VERSION "canboat-NMEA2000-curated"

NS_ :

BS_:

BU_: Vector__XXX
BO_ 2650734848 PGN_130817_furunoSvControl: 24 Vector__XXX
 SG_ Manufacturer_Code : 0|11@1+ (1.0,0) [0|2047] "" Vector__XXX
 SG_ Industry_Code : 13|3@1+ (1.0,0) [0|7] "" Vector__XXX
 SG_ F4 : 16|8@1+ (1.0,0) [0|255] "" Vector__XXX
 SG_ F5 : 24|8@1+ (1.0,0) [0|255] "" Vector__XXX
 SG_ SBAS_mode : 32|8@1+ (1.0,0) [0|255] "" Vector__XXX
 SG_ SBAS_satellite : 40|8@1+ (1.0,0) [0|255] "" Vector__XXX
 SG_ F8 : 48|16@1+ (1.0,0) [0|65535] "" Vector__XXX
 SG_ GPS_disable : 64|32@1+ (1.0,0) [0|4294967295] "" Vector__XXX
 SG_ GLONASS_disable : 96|32@1+ (1.0,0) [0|4294967295] "" Vector__XXX
 SG_ Galileo_disable : 128|40@1+ (1.0,0) [0|1099511627775] "" Vector__XXX
 SG_ QZSS_disable : 168|24@1+ (1.0,0) [0|16777215] "" Vector__XXX

BO_ 2650734848 PGN_130817_lowranceProductInformation: 113 Vector__XXX
 SG_ Manufacturer_Code : 0|11@1+ (1.0,0) [0|2047] "" Vector__XXX
 SG_ Industry_Code : 13|3@1+ (1.0,0) [0|7] "" Vector__XXX
 SG_ Product_Code : 16|16@1+ (1.0,0) [0|65535] "" Vector__XXX
 SG_ Model : 32|256@1+ (1.0,0) [0|115792089237316195423570985008687907853269984665640564039457584007913129639935] "" Vector__XXX
 SG_ A : 288|8@1+ (1.0,0) [0|255] "" Vector__XXX
 SG_ B : 296|8@1+ (1.0,0) [0|255] "" Vector__XXX
 SG_ C : 304|8@1+ (1.0,0) [0|255] "" Vector__XXX
 SG_ Firmware_version : 312|80@1+ (1.0,0) [0|1208925819614629174706175] "" Vector__XXX
 SG_ Firmware_date : 392|256@1+ (1.0,0) [0|115792089237316195423570985008687907853269984665640564039457584007913129639935] "" Vector__XXX
 SG_ Firmware_time : 648|256@1+ (1.0,0) [0|115792089237316195423570985008687907853269984665640564039457584007913129639935] "" Vector__XXX

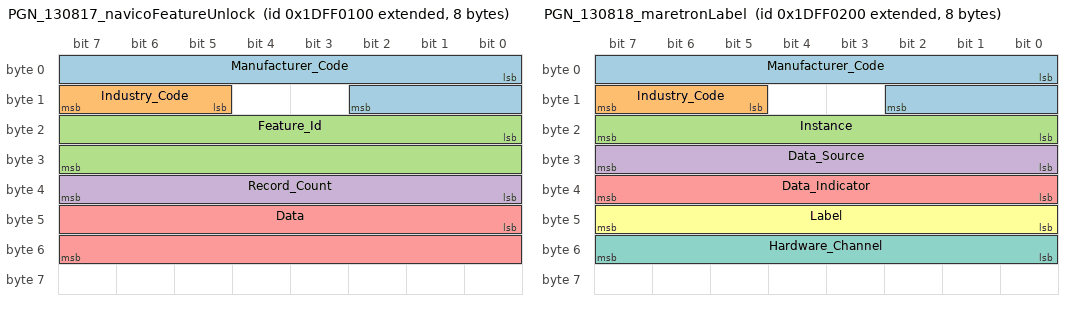
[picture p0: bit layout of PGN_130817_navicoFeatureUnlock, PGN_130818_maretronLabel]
BO_ 2650734848 PGN_130817_navicoFeatureUnlock: 8 Vector__XXX
 SG_ Manufacturer_Code : 0|11@1+ (1.0,0) [0|2047] "" Vector__XXX
 SG_ Industry_Code : 13|3@1+ (1.0,0) [0|7] "" Vector__XXX
 SG_ Feature_Id : 16|16@1+ (1.0,0) [0|65535] "" Vector__XXX
 SG_ Record_Count : 32|8@1+ (1.0,0) [0|255] "" Vector__XXX
 SG_ Data : 40|16@1+ (1.0,0) [0|65535] "" Vector__XXX

BO_ 2583626240 PGN_130818_bepMarineProprietaryPgn130818: 223 Vector__XXX
 SG_ Manufacturer_Code : 0|11@1+ (1.0,0) [0|2047] "" Vector__XXX
 SG_ Industry_Code : 13|3@1+ (1.0,0) [0|7] "" Vector__XXX
 SG_ Data : 16|1768@1+ (1.0,0) [0|16635364987126134419907490844611231857889171561340108669757218330385068731224834608417815051548234195819468783937845710359164977421616154908223175941492902641772198991471137845920843845811776377869137773379678289214194183661112800944378464511794046030758602257005203964634516091405743061582849883160885255175229773660916874237270946647032424101972117051870087763059119895517977437771543686400460392041962138103436564399831189767740372774280024852942859855049773927338342604171805121253257539126169331943684033945189625789470637817855] "" Vector__XXX

BO_ 2650735104 PGN_130818_furunoSensorSetup: 28 Vector__XXX
 SG_ Manufacturer_Code : 0|11@1+ (1.0,0) [0|2047] "" Vector__XXX
 SG_ Industry_Code : 13|3@1+ (1.0,0) [0|7] "" Vector__XXX
 SG_ Rotation_smoothing : 16|16@1+ (0.1,0) [0.0|6553.5] "" Vector__XXX
 SG_ Heading_offset : 32|16@1- (0.1,0) [-3276.8|3276.7000000000003] "deg" Vector__XXX
 SG_ Pitch_offset : 48|16@1- (0.1,0) [-3276.8|3276.7000000000003] "deg" Vector__XXX
 SG_ Roll_offset : 64|16@1- (0.1,0) [-3276.8|3276.7000000000003] "deg" Vector__XXX
 SG_ F8 : 80|8@1+ (1.0,0) [0|255] "" Vector__XXX
 SG_ F9 : 88|8@1+ (1.0,0) [0|255] "" Vector__XXX
 SG_ SOG_and_COG_smoothing : 96|32@1- (0.001,0) [-2147483.648|2147483.647] "" Vector__XXX
 SG_ _3_Axis_speed_smoothing : 128|32@1- (0.001,0) [-2147483.648|2147483.647] "" Vector__XXX
 SG_ FC : 160|16@1+ (1.0,0) [0|65535] "" Vector__XXX
 SG_ _3_axis_offset : 176|16@1- (0.00032,0) [-12.5|12.5] "%" Vector__XXX
 SG_ Air_pressure_offset : 192|16@1- (10.0,0) [-99.9|99.9] "Pa" Vector__XXX
 SG_ Air_temperature_offset : 208|16@1- (0.1,0) [-99.9|99.9] "K" Vector__XXX

BO_ 2650735104 PGN_130818_maretronLabel: 8 Vector__XXX
 SG_ Manufacturer_Code : 0|11@1+ (1.0,0) [0|2047] "" Vector__XXX
 SG_ Industry_Code : 13|3@1+ (1.0,0) [0|7] "" Vector__XXX
 SG_ Instance : 16|8@1+ (1.0,0) [0|255] "" Vector__XXX
 SG_ Data_Source : 24|8@1+ (1.0,0) [0|255] "" Vector__XXX
 SG_ Data_Indicator : 32|8@1+ (1.0,0) [0|255] "" Vector__XXX
 SG_ Label : 40|8@1+ (1.0,0) [0|255] "" Vector__XXX
 SG_ Hardware_Channel : 48|8@1+ (1.0,0) [0|255] "" Vector__XXX

BO_ 2650735104 PGN_130818_simnetReprogramData: 223 Vector__XXX
 SG_ Manufacturer_Code : 0|11@1+ (1.0,0) [0|2047] "" Vector__XXX
 SG_ Industry_Code : 13|3@1+ (1.0,0) [0|7] "" Vector__XXX
 SG_ Version : 16|16@1+ (1.0,0) [0|65535] "" Vector__XXX
 SG_ Sequence : 32|16@1+ (1.0,0) [0|65535] "" Vector__XXX
 SG_ Data : 48|1736@1+ (1.0,0) [0|3873222737369624529943682915673412349514935994832801788523145562593142672261417519398456218547242273534524437025619137650161277833770996636763023198929825481439986962701924575008648411792650906804282631114981670215305449362172000330029629290055959958294081095840130924394940047386508216518640956646037580253377038440880569218953826149700308242340599431626053471830468600503629408257907183468449020768041288969907109718730484547033061453672131722081187147425900662163817930075294599228831366432404455715716824388408480628735] "" Vector__XXX

BO_ 2583626240 PGN_130818_webastoStatus2: 14 Vector__XXX
 SG_ Manufacturer_Code : 0|11@1+ (1.0,0) [0|2047] "" Vector__XXX
 SG_ Industry_Code : 13|3@1+ (1.0,0) [0|7] "" Vector__XXX
 SG_ CAN_Address : 16|8@1+ (1.0,0) [0|255] "" Vector__XXX
 SG_ Device_ID : 24|8@1+ (1.0,0) [0|255] "" Vector__XXX
 SG_ System_Error : 32|32@1+ (1.0,0) [0|4294967295] "" Vector__XXX
 SG_ System_Status : 64|32@1+ (1.0,0) [0|4294967295] "" Vector__XXX
 SG_ Fresh_Air_Blower_Speed : 96|8@1+ (1.0,0) [0|255] "" Vector__XXX
 SG_ V_Series_Output : 104|8@1+ (1.0,0) [0|255] "" Vector__XXX

BO_ 2583626496 PGN_130819_bepMarineCzone130819: 15 Vector__XXX
 SG_ Manufacturer_Code : 0|11@1+ (1.0,0) [0|2047] "" Vector__XXX
 SG_ Industry_Code : 13|3@1+ (1.0,0) [0|7] "" Vector__XXX
 SG_ Field_A : 16|16@1+ (1.0,0) [0|65535] "" Vector__XXX
 SG_ Field_B : 32|8@1+ (1.0,0) [0|255] "" Vector__XXX
 SG_ Field_C : 40|8@1+ (1.0,0) [0|255] "" Vector__XXX
 SG_ Field_D : 48|8@1+ (1.0,0) [0|255] "" Vector__XXX
 SG_ Field_E : 56|16@1+ (1.0,0) [0|65535] "" Vector__XXX
 SG_ Field_F : 72|32@1+ (1.0,0) [0|4294967295] "" Vector__XXX
 SG_ Field_G : 104|8@1+ (1.0,0) [0|255] "" Vector__XXX
 SG_ Flag : 112|8@1+ (1.0,0) [0|255] "" Vector__XXX

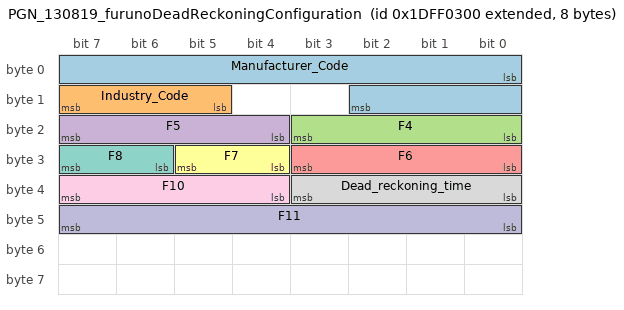
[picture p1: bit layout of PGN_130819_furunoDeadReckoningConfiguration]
BO_ 2650735360 PGN_130819_furunoDeadReckoningConfiguration: 8 Vector__XXX
 SG_ Manufacturer_Code : 0|11@1+ (1.0,0) [0|2047] "" Vector__XXX
 SG_ Industry_Code : 13|3@1+ (1.0,0) [0|7] "" Vector__XXX
 SG_ F4 : 16|4@1+ (1.0,0) [0|15] "" Vector__XXX
 SG_ F5 : 20|4@1+ (1.0,0) [0|15] "" Vector__XXX
 SG_ F6 : 24|4@1+ (1.0,0) [0|15] "" Vector__XXX
 SG_ F7 : 28|2@1+ (1.0,0) [0|3] "" Vector__XXX
 SG_ F8 : 30|2@1+ (1.0,0) [0|3] "" Vector__XXX
 SG_ Dead_reckoning_time : 32|4@1+ (1.0,0) [0|15] "" Vector__XXX
 SG_ F10 : 36|4@1+ (1.0,0) [0|15] "" Vector__XXX
 SG_ F11 : 40|8@1+ (1.0,0) [0|255] "" Vector__XXX

BO_ 2650735360 PGN_130819_maretronAlertTransmission: 34 Vector__XXX
 SG_ Manufacturer_Code : 0|11@1+ (1.0,0) [0|2047] "" Vector__XXX
 SG_ Industry_Code : 13|3@1+ (1.0,0) [0|7] "" Vector__XXX
 SG_ Alert_Type : 16|4@1+ (1.0,0) [0|15] "" Vector__XXX
 SG_ Alert_Category : 20|4@1+ (1.0,0) [0|15] "" Vector__XXX
 SG_ Alert_System : 24|8@1+ (1.0,0) [0|255] "" Vector__XXX
 SG_ Alert_Sub_System : 32|8@1+ (1.0,0) [0|255] "" Vector__XXX
 SG_ Alert_ID : 40|16@1+ (1.0,0) [0|65535] "" Vector__XXX
 SG_ Data_Source_Network_ID_NAME : 56|64@1+ (1.0,0) [0|18446744073709551615] "" Vector__XXX
 SG_ Data_Source_Instance : 120|8@1+ (1.0,0) [0|255] "" Vector__XXX
 SG_ Data_Source_Index_Source : 128|8@1+ (1.0,0) [0|255] "" Vector__XXX
 SG_ Alert_Occurrence_Number : 136|8@1+ (1.0,0) [0|255] "" Vector__XXX
 SG_ Maretron_Extension : 144|128@1+ (1.0,0) [0|340282366920938463463374607431768211455] "" Vector__XXX

BO_ 2650735360 PGN_130819_simnetRequestReprogram: 8 Vector__XXX
 SG_ Manufacturer_Code : 0|11@1+ (1.0,0) [0|2047] "" Vector__XXX
 SG_ Industry_Code : 13|3@1+ (1.0,0) [0|7] "" Vector__XXX

BO_ 2382299904 PGN_130819_webastoHvacCommand: 9 Vector__XXX
 SG_ Manufacturer_Code : 0|11@1+ (1.0,0) [0|2047] "" Vector__XXX
 SG_ Industry_Code : 13|3@1+ (1.0,0) [0|7] "" Vector__XXX
 SG_ CAN_Address : 16|8@1+ (1.0,0) [0|255] "" Vector__XXX
 SG_ Blower_Speed : 24|8@1+ (1.0,0) [0|255] "" Vector__XXX
 SG_ Unit_On_Off : 32|2@1+ (1.0,0) [0|3] "" Vector__XXX
 SG_ Set_Temperature : 40|16@1+ (0.01,0) [0.0|655.35] "" Vector__XXX
 SG_ ECO_Mode : 56|2@1+ (1.0,0) [0|3] "" Vector__XXX
 SG_ Functional_Mode : 58|2@1+ (1.0,0) [0|3] "" Vector__XXX
 SG_ Compressor : 60|2@1+ (1.0,0) [0|3] "" Vector__XXX
 SG_ Mask : 64|8@1+ (1.0,0) [0|255] "" Vector__XXX

BO_ 2583626752 PGN_130820_bepMarineCzoneAlarmStringResponse: 222 Vector__XXX
 SG_ Manufacturer_Code : 0|11@1+ (1.0,0) [0|2047] "" Vector__XXX
 SG_ Industry_Code : 13|3@1+ (1.0,0) [0|7] "" Vector__XXX
 SG_ Device_ID : 16|8@1+ (1.0,0) [0|255] "" Vector__XXX
 SG_ Channel : 24|16@1+ (1.0,0) [0|65535] "" Vector__XXX
 SG_ String : 40|1736@1+ (1.0,0) [0|3873222737369624529943682915673412349514935994832801788523145562593142672261417519398456218547242273534524437025619137650161277833770996636763023198929825481439986962701924575008648411792650906804282631114981670215305449362172000330029629290055959958294081095840130924394940047386508216518640956646037580253377038440880569218953826149700308242340599431626053471830468600503629408257907183468449020768041288969907109718730484547033061453672131722081187147425900662163817930075294599228831366432404455715716824388408480628735] "" Vector__XXX

BO_ 2650735616 PGN_130820_furunoUnknown130820: 8 Vector__XXX

BO_ 2650735616 PGN_130820_fusionAlbumName: 10 Vector__XXX

BO_ 2650735616 PGN_130820_fusionArtistName: 10 Vector__XXX

BO_ 2650735616 PGN_130820_fusionAuxGain: 8 Vector__XXX

BO_ 2650735616 PGN_130820_fusionBalance: 8 Vector__XXX

BO_ 2650735616 PGN_130820_fusionCapabilities: 14 Vector__XXX

BO_ 2650735616 PGN_130820_fusionDeviceName: 8 Vector__XXX

BO_ 2650735616 PGN_130820_fusionEq: 8 Vector__XXX

BO_ 2650735616 PGN_130820_fusionIgnitionSwitchState: 8 Vector__XXX

BO_ 2650735616 PGN_130820_fusionLineLevelControl: 8 Vector__XXX

BO_ 2650735616 PGN_130820_fusionLowPassFilter: 8 Vector__XXX

BO_ 2650735616 PGN_130820_fusionMarineScanMode: 8 Vector__XXX

BO_ 2650735616 PGN_130820_fusionMarineSquelch: 8 Vector__XXX

BO_ 2650735616 PGN_130820_fusionMarineTuner: 8 Vector__XXX

BO_ 2650735616 PGN_130820_fusionMedia: 23 Vector__XXX

BO_ 2650735616 PGN_130820_fusionMenuActionStatus: 11 Vector__XXX

BO_ 2650735616 PGN_130820_fusionMenuCount: 10 Vector__XXX

BO_ 2650735616 PGN_130820_fusionMenuItem: 12 Vector__XXX

BO_ 2650735616 PGN_130820_fusionMenuLockId: 9 Vector__XXX

BO_ 2650735616 PGN_130820_fusionMono: 8 Vector__XXX

BO_ 2650735616 PGN_130820_fusionMultiroom: 9 Vector__XXX

BO_ 2650735616 PGN_130820_fusionMultiroomStatus: 8 Vector__XXX

BO_ 2650735616 PGN_130820_fusionMute: 8 Vector__XXX

BO_ 2650735616 PGN_130820_fusionPowerState: 8 Vector__XXX

BO_ 2650735616 PGN_130820_fusionProcessingBypass: 8 Vector__XXX

BO_ 2650735616 PGN_130820_fusionRdsData: 39 Vector__XXX

BO_ 2650735616 PGN_130820_fusionSetting: 12 Vector__XXX

BO_ 2650735616 PGN_130820_fusionSettings: 9 Vector__XXX

BO_ 2650735616 PGN_130820_fusionSiriusxm: 10 Vector__XXX

BO_ 2650735616 PGN_130820_fusionSiriusxmArtist: 8 Vector__XXX

BO_ 2650735616 PGN_130820_fusionSiriusxmCategory: 8 Vector__XXX

BO_ 2650735616 PGN_130820_fusionSiriusxmChannel: 8 Vector__XXX

BO_ 2650735616 PGN_130820_fusionSiriusxmContentInfo: 8 Vector__XXX

BO_ 2650735616 PGN_130820_fusionSiriusxmPresets: 8 Vector__XXX

BO_ 2650735616 PGN_130820_fusionSiriusxmSignal: 8 Vector__XXX

BO_ 2650735616 PGN_130820_fusionSiriusxmTitle: 8 Vector__XXX

BO_ 2650735616 PGN_130820_fusionSource: 9 Vector__XXX

BO_ 2650735616 PGN_130820_fusionSourceCount: 8 Vector__XXX

BO_ 2650735616 PGN_130820_fusionSpeedVolumeCurrentSpeed: 8 Vector__XXX

BO_ 2650735616 PGN_130820_fusionSublevels: 8 Vector__XXX

BO_ 2650735616 PGN_130820_fusionTrackName: 10 Vector__XXX

BO_ 2650735616 PGN_130820_fusionTrackPosition: 8 Vector__XXX

BO_ 2650735616 PGN_130820_fusionTuner: 12 Vector__XXX

BO_ 2650735616 PGN_130820_fusionUsbRepeatStatus: 12 Vector__XXX

BO_ 2650735616 PGN_130820_fusionVersions: 11 Vector__XXX

BO_ 2650735616 PGN_130820_fusionVolumeLimits: 8 Vector__XXX

BO_ 2650735616 PGN_130820_fusionVolumes: 8 Vector__XXX

BO_ 2650735616 PGN_130820_fusionZoneName: 8 Vector__XXX

BO_ 2650735616 PGN_130820_maretronAlertResponse: 27 Vector__XXX

BO_ 2650735616 PGN_130820_simnetReprogramStatus: 8 Vector__XXX

CM_ BO_ 2650734848 "NMEA2000: PGN 130817 - Furuno: SV control (type: Fast)";
CM_ BO_ 2650734848 "NMEA2000: PGN 130817 - Lowrance: Product Information (type: Fast)";
CM_ BO_ 2650734848 "NMEA2000: PGN 130817 - Navico: Feature Unlock (type: Fast)";
CM_ BO_ 2583626240 "NMEA2000: PGN 130818 - BEP Marine: Proprietary PGN 130818 (type: Fast)";
CM_ BO_ 2650735104 "NMEA2000: PGN 130818 - Furuno: Sensor setup (type: Fast)";
CM_ BO_ 2650735104 "NMEA2000: PGN 130818 - Maretron: Label (type: Fast)";
CM_ BO_ 2650735104 "NMEA2000: PGN 130818 - Simnet: Reprogram Data (type: Fast)";
CM_ BO_ 2583626240 "NMEA2000: PGN 130818 - Webasto: Status 2 (type: Fast)";
CM_ BO_ 2583626496 "NMEA2000: PGN 130819 - BEP Marine: CZone 130819 (type: Fast)";
CM_ BO_ 2650735360 "NMEA2000: PGN 130819 - Furuno: Dead Reckoning Configuration (type: Fast)";
CM_ BO_ 2650735360 "NMEA2000: PGN 130819 - Maretron: Alert Transmission (type: Fast)";
CM_ BO_ 2650735360 "NMEA2000: PGN 130819 - Simnet: Request Reprogram (type: Fast)";
CM_ BO_ 2382299904 "NMEA2000: PGN 130819 - Webasto: HVAC Command (type: Fast)";
CM_ BO_ 2583626752 "NMEA2000: PGN 130820 - BEP Marine: CZone Alarm String Response (type: Fast)";
CM_ BO_ 2650735616 "NMEA2000: PGN 130820 - Furuno: Unknown 130820 (type: Fast)";
CM_ BO_ 2650735616 "NMEA2000: PGN 130820 - Fusion: Album Name (type: Fast)";
CM_ BO_ 2650735616 "NMEA2000: PGN 130820 - Fusion: Artist Name (type: Fast)";
CM_ BO_ 2650735616 "NMEA2000: PGN 130820 - Fusion: Aux Gain (type: Fast)";
CM_ BO_ 2650735616 "NMEA2000: PGN 130820 - Fusion: Balance (type: Fast)";
CM_ BO_ 2650735616 "NMEA2000: PGN 130820 - Fusion: Capabilities (type: Fast)";
CM_ BO_ 2650735616 "NMEA2000: PGN 130820 - Fusion: Device Name (type: Fast)";
CM_ BO_ 2650735616 "NMEA2000: PGN 130820 - Fusion: EQ (type: Fast)";
CM_ BO_ 2650735616 "NMEA2000: PGN 130820 - Fusion: Ignition Switch State (type: Fast)";
CM_ BO_ 2650735616 "NMEA2000: PGN 130820 - Fusion: Line Level Control (type: Fast)";
CM_ BO_ 2650735616 "NMEA2000: PGN 130820 - Fusion: Low Pass Filter (type: Fast)";
CM_ BO_ 2650735616 "NMEA2000: PGN 130820 - Fusion: Marine Scan Mode (type: Fast)";
CM_ BO_ 2650735616 "NMEA2000: PGN 130820 - Fusion: Marine Squelch (type: Fast)";
CM_ BO_ 2650735616 "NMEA2000: PGN 130820 - Fusion: MARINE_TUNER (type: Fast)";
CM_ BO_ 2650735616 "NMEA2000: PGN 130820 - Fusion: Media (type: Fast)";
CM_ BO_ 2650735616 "NMEA2000: PGN 130820 - Fusion: Menu Action Status (type: Fast)";
CM_ BO_ 2650735616 "NMEA2000: PGN 130820 - Fusion: Menu Count (type: Fast)";
CM_ BO_ 2650735616 "NMEA2000: PGN 130820 - Fusion: Menu Item (type: Fast)";
CM_ BO_ 2650735616 "NMEA2000: PGN 130820 - Fusion: Menu Lock Id (type: Fast)";
CM_ BO_ 2650735616 "NMEA2000: PGN 130820 - Fusion: Mono (type: Fast)";
CM_ BO_ 2650735616 "NMEA2000: PGN 130820 - Fusion: Multiroom (type: Fast)";
CM_ BO_ 2650735616 "NMEA2000: PGN 130820 - Fusion: Multiroom Status (type: Fast)";
CM_ BO_ 2650735616 "NMEA2000: PGN 130820 - Fusion: Mute (type: Fast)";
CM_ BO_ 2650735616 "NMEA2000: PGN 130820 - Fusion: Power State (type: Fast)";
CM_ BO_ 2650735616 "NMEA2000: PGN 130820 - Fusion: Processing Bypass (type: Fast)";
CM_ BO_ 2650735616 "NMEA2000: PGN 130820 - Fusion: RDS Data (type: Fast)";
CM_ BO_ 2650735616 "NMEA2000: PGN 130820 - Fusion: Setting (type: Fast)";
CM_ BO_ 2650735616 "NMEA2000: PGN 130820 - Fusion: Settings (type: Fast)";
CM_ BO_ 2650735616 "NMEA2000: PGN 130820 - Fusion: SiriusXM (type: Fast)";
CM_ BO_ 2650735616 "NMEA2000: PGN 130820 - Fusion: SiriusXM Artist (type: Fast)";
CM_ BO_ 2650735616 "NMEA2000: PGN 130820 - Fusion: SiriusXM Category (type: Fast)";
CM_ BO_ 2650735616 "NMEA2000: PGN 130820 - Fusion: SiriusXM Channel (type: Fast)";
CM_ BO_ 2650735616 "NMEA2000: PGN 130820 - Fusion: SiriusXM Content Info (type: Fast)";
CM_ BO_ 2650735616 "NMEA2000: PGN 130820 - Fusion: SiriusXM Presets (type: Fast)";
CM_ BO_ 2650735616 "NMEA2000: PGN 130820 - Fusion: SiriusXM Signal (type: Fast)";
CM_ BO_ 2650735616 "NMEA2000: PGN 130820 - Fusion: SiriusXM Title (type: Fast)";
CM_ BO_ 2650735616 "NMEA2000: PGN 130820 - Fusion: Source (type: Fast)";
CM_ BO_ 2650735616 "NMEA2000: PGN 130820 - Fusion: Source Count (type: Fast)";
CM_ BO_ 2650735616 "NMEA2000: PGN 130820 - Fusion: Speed Volume Current Speed (type: Fast)";
CM_ BO_ 2650735616 "NMEA2000: PGN 130820 - Fusion: Sublevels (type: Fast)";
CM_ BO_ 2650735616 "NMEA2000: PGN 130820 - Fusion: Track Name (type: Fast)";
CM_ BO_ 2650735616 "NMEA2000: PGN 130820 - Fusion: Track Position (type: Fast)";
CM_ BO_ 2650735616 "NMEA2000: PGN 130820 - Fusion: Tuner (type: Fast)";
CM_ BO_ 2650735616 "NMEA2000: PGN 130820 - Fusion: USB Repeat Status (type: Fast)";
CM_ BO_ 2650735616 "NMEA2000: PGN 130820 - Fusion: Versions (type: Fast)";
CM_ BO_ 2650735616 "NMEA2000: PGN 130820 - Fusion: Volume Limits (type: Fast)";
CM_ BO_ 2650735616 "NMEA2000: PGN 130820 - Fusion: Volumes (type: Fast)";
CM_ BO_ 2650735616 "NMEA2000: PGN 130820 - Fusion: Zone Name (type: Fast)";
CM_ BO_ 2650735616 "NMEA2000: PGN 130820 - Maretron: Alert Response (type: Fast)";
CM_ BO_ 2650735616 "NMEA2000: PGN 130820 - Simnet: Reprogram Status (type: Fast)";
CM_ SG_ 2650734848 Manufacturer_Code "Furuno; canboat type: LOOKUP";
CM_ SG_ 2650734848 Industry_Code "Marine Industry; canboat type: LOOKUP";
CM_ SG_ 2650734848 F4 "Unknown; canboat type: BINARY";
CM_ SG_ 2650734848 F5 "Unknown; canboat type: BINARY";
CM_ SG_ 2650734848 SBAS_mode "canboat type: LOOKUP";
CM_ SG_ 2650734848 SBAS_satellite "canboat type: LOOKUP";
CM_ SG_ 2650734848 F8 "Unknown; canboat type: BINARY";
CM_ SG_ 2650734848 GPS_disable "canboat type: BITLOOKUP";
CM_ SG_ 2650734848 GLONASS_disable "canboat type: BITLOOKUP";
CM_ SG_ 2650734848 Galileo_disable "canboat type: BITLOOKUP";
CM_ SG_ 2650734848 QZSS_disable "canboat type: BITLOOKUP";
CM_ SG_ 2650734848 Manufacturer_Code "Lowrance; canboat type: LOOKUP";
CM_ SG_ 2650734848 Industry_Code "Marine Industry; canboat type: LOOKUP";
CM_ SG_ 2650734848 Product_Code "canboat type: UINT16";
CM_ SG_ 2650734848 Model "canboat type: STRING_FIX";
CM_ SG_ 2650734848 A "canboat type: UINT8";
CM_ SG_ 2650734848 B "canboat type: UINT8";
CM_ SG_ 2650734848 C "canboat type: UINT8";
CM_ SG_ 2650734848 Firmware_version "canboat type: STRING_FIX";
CM_ SG_ 2650734848 Firmware_date "canboat type: STRING_FIX";
CM_ SG_ 2650734848 Firmware_time "canboat type: STRING_FIX";
CM_ SG_ 2650734848 Manufacturer_Code "Navico; canboat type: LOOKUP";
CM_ SG_ 2650734848 Industry_Code "Marine Industry; canboat type: LOOKUP";
CM_ SG_ 2650734848 Feature_Id "Feature/object identifier. A 126208 Request for this PGN filters on this value as its field 4 (the requester asks the target to report a specific feature).; canboat type: UINT16";
CM_ SG_ 2650734848 Record_Count "Number of 3-byte records that follow; 0 in every observed broadcast; canboat type: UINT8";
CM_ SG_ 2650734848 Data "Trailing value (observed only with Record Count 0); canboat type: UINT16";
CM_ SG_ 2583626240 Manufacturer_Code "BEP Marine; canboat type: LOOKUP";
CM_ SG_ 2583626240 Industry_Code "Marine Industry; canboat type: LOOKUP";
CM_ SG_ 2583626240 Data "canboat type: BINARY";
CM_ SG_ 2650735104 Manufacturer_Code "Furuno; canboat type: LOOKUP";
CM_ SG_ 2650735104 Industry_Code "Marine Industry; canboat type: LOOKUP";
CM_ SG_ 2650735104 Rotation_smoothing "canboat type: DURATION_UFIX16_DS";
CM_ SG_ 2650735104 Heading_offset "canboat type: ANGLE_FIX16_DDEG";
CM_ SG_ 2650735104 Pitch_offset "canboat type: ANGLE_FIX16_DDEG";
CM_ SG_ 2650735104 Roll_offset "canboat type: ANGLE_FIX16_DDEG";
CM_ SG_ 2650735104 F8 "canboat type: UINT8";
CM_ SG_ 2650735104 F9 "canboat type: UINT8";
CM_ SG_ 2650735104 SOG_and_COG_smoothing "canboat type: DURATION_FIX32_MS";
CM_ SG_ 2650735104 _3_Axis_speed_smoothing "canboat type: DURATION_FIX32_MS";
CM_ SG_ 2650735104 FC "canboat type: UINT16";
CM_ SG_ 2650735104 _3_axis_offset "canboat type: INT16";
CM_ SG_ 2650735104 Air_pressure_offset "canboat type: INT16";
CM_ SG_ 2650735104 Air_temperature_offset "canboat type: FIX16_1";
CM_ SG_ 2650735104 Manufacturer_Code "Maretron; canboat type: LOOKUP";
CM_ SG_ 2650735104 Industry_Code "Marine Industry; canboat type: LOOKUP";
CM_ SG_ 2650735104 Instance "canboat type: UINT8";
CM_ SG_ 2650735104 Data_Source "canboat type: UINT8";
CM_ SG_ 2650735104 Data_Indicator "canboat type: UINT8";
CM_ SG_ 2650735104 Label "canboat type: STRING_LAU";
CM_ SG_ 2650735104 Hardware_Channel "canboat type: UINT8";
CM_ SG_ 2650735104 Manufacturer_Code "Simrad; canboat type: LOOKUP";
CM_ SG_ 2650735104 Industry_Code "Marine Industry; canboat type: LOOKUP";
CM_ SG_ 2650735104 Version "canboat type: UINT16";
CM_ SG_ 2650735104 Sequence "canboat type: UINT16";
CM_ SG_ 2650735104 Data "canboat type: BINARY";
CM_ SG_ 2583626240 Manufacturer_Code "Webasto; canboat type: LOOKUP";
CM_ SG_ 2583626240 Industry_Code "Marine Industry; canboat type: LOOKUP";
CM_ SG_ 2583626240 CAN_Address "canboat type: UINT8";
CM_ SG_ 2583626240 Device_ID "canboat type: UINT8";
CM_ SG_ 2583626240 System_Error "canboat type: UINT32";
CM_ SG_ 2583626240 System_Status "canboat type: UINT32";
CM_ SG_ 2583626240 Fresh_Air_Blower_Speed "canboat type: UINT8";
CM_ SG_ 2583626240 V_Series_Output "canboat type: UINT8";
CM_ SG_ 2583626496 Manufacturer_Code "BEP Marine; canboat type: LOOKUP";
CM_ SG_ 2583626496 Industry_Code "Marine Industry; canboat type: LOOKUP";
CM_ SG_ 2583626496 Field_A "uint16 LE; purpose unverified; canboat type: UINT16";
CM_ SG_ 2583626496 Field_B "Pass-through byte; purpose unverified; canboat type: UINT8";
CM_ SG_ 2583626496 Field_C "Pass-through byte; purpose unverified; canboat type: UINT8";
CM_ SG_ 2583626496 Field_D "Pass-through byte; purpose unverified; canboat type: UINT8";
CM_ SG_ 2583626496 Field_E "uint16 LE; purpose unverified; canboat type: UINT16";
CM_ SG_ 2583626496 Field_F "uint32 LE; top byte always 0 (effectively 24-bit). Purpose unverified.; canboat type: UINT32";
CM_ SG_ 2583626496 Field_G "Pass-through byte; purpose unverified; canboat type: UINT8";
CM_ SG_ 2583626496 Flag "Boolean encoded as 0xFE = false, 0xFF = true; purpose unverified; canboat type: UINT8";
CM_ SG_ 2650735360 Manufacturer_Code "Furuno; canboat type: LOOKUP";
CM_ SG_ 2650735360 Industry_Code "Marine Industry; canboat type: LOOKUP";
CM_ SG_ 2650735360 F4 "canboat type: UNSIGNED_INTEGER";
CM_ SG_ 2650735360 F5 "canboat type: UNSIGNED_INTEGER";
CM_ SG_ 2650735360 F6 "canboat type: UNSIGNED_INTEGER";
CM_ SG_ 2650735360 F7 "canboat type: UNSIGNED_INTEGER";
CM_ SG_ 2650735360 F8 "canboat type: UNSIGNED_INTEGER";
CM_ SG_ 2650735360 Dead_reckoning_time "0=5min, 1=4min, 2=3min, 3=2min, 4=1min (code = 5 - minutes); canboat type: UNSIGNED_INTEGER";
CM_ SG_ 2650735360 F10 "canboat type: UNSIGNED_INTEGER";
CM_ SG_ 2650735360 F11 "canboat type: UINT8";
CM_ SG_ 2650735360 Manufacturer_Code "Maretron; canboat type: LOOKUP";
CM_ SG_ 2650735360 Industry_Code "Marine Industry; canboat type: LOOKUP";
CM_ SG_ 2650735360 Alert_Type "canboat type: LOOKUP";
CM_ SG_ 2650735360 Alert_Category "canboat type: LOOKUP";
CM_ SG_ 2650735360 Alert_System "canboat type: UINT8";
CM_ SG_ 2650735360 Alert_Sub_System "canboat type: UINT8";
CM_ SG_ 2650735360 Alert_ID "canboat type: UINT16";
CM_ SG_ 2650735360 Data_Source_Network_ID_NAME "canboat type: ISO_NAME";
CM_ SG_ 2650735360 Data_Source_Instance "canboat type: UINT8";
CM_ SG_ 2650735360 Data_Source_Index_Source "canboat type: UINT8";
CM_ SG_ 2650735360 Alert_Occurrence_Number "canboat type: UINT8";
CM_ SG_ 2650735360 Maretron_Extension "Maretron-specific payload following the standard Alert identity header.; canboat type: BINARY";
CM_ SG_ 2650735360 Manufacturer_Code "Simrad; canboat type: LOOKUP";
CM_ SG_ 2650735360 Industry_Code "Marine Industry; canboat type: LOOKUP";
CM_ SG_ 2382299904 Manufacturer_Code "Webasto; canboat type: LOOKUP";
CM_ SG_ 2382299904 Industry_Code "Marine Industry; canboat type: LOOKUP";
CM_ SG_ 2382299904 CAN_Address "canboat type: UINT8";
CM_ SG_ 2382299904 Blower_Speed "canboat type: UINT8";
CM_ SG_ 2382299904 Unit_On_Off "canboat type: LOOKUP";
CM_ SG_ 2382299904 Set_Temperature "canboat type: TEMPERATURE";
CM_ SG_ 2382299904 ECO_Mode "canboat type: UNSIGNED_INTEGER";
CM_ SG_ 2382299904 Functional_Mode "canboat type: UNSIGNED_INTEGER";
CM_ SG_ 2382299904 Compressor "canboat type: UNSIGNED_INTEGER";
CM_ SG_ 2382299904 Mask "canboat type: UINT8";
CM_ SG_ 2583626752 Manufacturer_Code "BEP Marine; canboat type: LOOKUP";
CM_ SG_ 2583626752 Industry_Code "Marine Industry; canboat type: LOOKUP";
CM_ SG_ 2583626752 Device_ID "Device / source module id, echoed from the triggering PGN 65299; canboat type: UINT8";
CM_ SG_ 2583626752 Channel "Channel / alarm id, echoed from the triggering PGN 65299; canboat type: UINT16";
CM_ SG_ 2583626752 String "Variable-length NUL-terminated alarm string (up to 217 bytes); ASCII or UTF-8 not yet confirmed; canboat type: BINARY";
VAL_ 2650734848 Manufacturer_Code 69 "ARKS Enterprises" 78 "FW Murphy/Enovation Controls" 80 "Twin Disc" 85 "Kohler Power Systems" 88 "Hemisphere GPS" 135 "Airmar" 137 "Maretron" 140 "Lowrance" 144 "Mercury Marine" 147 "Nautibus Electronic" 148 "Blue Water Data" 154 "Westerbeke" 157 "ISSPRO" 161 "Offshore Systems (UK)" 163 "Evinrude/BRP" 165 "CPAC Systems" 168 "Xantrex Technology" 169 "Marlin Technologies" 172 "Yanmar Marine" 174 "Volvo Penta" 176 "Carling Technologies Inc. (Moritz Aerospace)" 185 "Beede Instruments" 192 "Floscan Instrument" 193 "Nobeltec" 198 "Mystic Valley Communications" 199 "Actia" 201 "Disenos Y Technologia" 211 "Digital Switching Systems" 215 "Xintex/Atena" 224 "EMMI NETWORK" 228 "ZF" 229 "Garmin" 233 "Yacht Monitoring Solutions" 235 "Sailormade Marine Telemetry/Tetra Technology" 243 "Eride" 257 "Honda Motor" 272 "Groco" 273 "Actisense" 274 "Amphenol LTW Technology" 275 "Navico" 283 "Hamilton Jet" 285 "Sea Recovery" 286 "Coelmo SRL Italy" 295 "BEP Marine" 304 "Empir Bus" 305 "NovAtel" 306 "Sleipner Motor" 307 "MBW Technologies" 315 "ICOM" 328 "Qwerty" 329 "Dief" 341 "Boening Automationstechnologie" 345 "Korean Maritime University" 351 "Thrane and Thrane" 355 "Mastervolt" 356 "Fischer Panda Generators" 358 "Victron Energy" 370 "Rolls Royce Marine" 373 "Electronic Design" 374 "Northern Lights" 378 "Glendinning" 381 "B & G" 384 "Rose Point Navigation Systems" 385 "Johnson Outdoors Marine Electronics Inc Geonav" 394 "Capi 2" 396 "Beyond Measure" 400 "Livorsi Marine" 404 "ComNav" 409 "Chetco" 419 "Fusion Electronics" 421 "Standard Horizon" 422 "True Heading" 426 "Egersund Marine Electronics" 427 "em-trak Marine Electronics" 431 "Tohatsu Co, JP" 437 "Digital Yacht" 438 "Comar Systems Limited" 440 "Cummins" 443 "VDO (aka Continental-Corporation)" 451 "Parker Hannifin aka Village Marine Tech" 459 "Alltek Marine Electronics" 460 "SAN GIORGIO S.E.I.N" 466 "Veethree Electronics & Marine" 470 "SI-TEX Marine Electronics" 471 "Sea Cross Marine" 475 "GME aka Standard Communications" 476 "Humminbird Marine Electronics" 478 "Ocean Sat" 481 "Chetco Digital Instruments" 493 "Watcheye" 499 "Lcj Capteurs" 502 "Attwood Marine" 503 "Naviop S.R.L." 504 "Vesper Marine" 510 "Marinesoft" 513 "Simarine" 517 "NoLand Engineering" 518 "Transas USA" 529 "National Instruments Korea" 530 "National Marine Electronics Association" 532 "Onwa Marine" 540 "Webasto" 571 "Marinecraft (South Korea)" 573 "McMurdo Group aka Orolia" 578 "Advansea" 579 "KVH" 580 "San Jose Technology" 583 "Yacht Control" 586 "Suzuki Motor" 591 "US Coast Guard" 595 "Ship Module aka Customware" 600 "Aquatic AV" 605 "Aventics" 606 "Intellian" 612 "SamwonIT" 614 "Arlt Tecnologies" 637 "Bavaria Yachts" 641 "Diverse Yacht Services" 644 "Wema U.S.A dba KUS" 658 "Shenzhen Jiuzhou Himunication" 688 "Rockford" 699 "Harman International" 704 "JL Audio" 708 "Lars Thrane" 715 "Autonnic" 717 "Yacht Devices" 734 "REAP Systems" 735 "AEM Performance Electronics" 739 "LxNav" 741 "Littelfuse, Inc (formerly Carling Technologies)" 743 "DaeMyung" 744 "Woosung" 748 "ISOTTA IFRA srl" 773 "Clarion US" 776 "HMI Systems" 777 "Ocean Signal" 778 "Seakeeper" 781 "Poly Planar" 785 "Fischer Panda DE" 795 "Broyda Industries" 796 "Canadian Automotive" 797 "Tides Marine" 798 "Lumishore" 799 "Still Water Designs and Audio" 802 "BJ Technologies (Beneteau)" 803 "Gill Sensors" 811 "Blue Water Desalination" 815 "FLIR" 824 "Undheim Systems" 826 "Lewmar" 838 "TeamSurv" 844 "Fell Marine" 847 "Oceanvolt" 862 "Prospec" 868 "Data Panel" 890 "L3 Technologies" 894 "Rhodan Marine Systems" 896 "Nexfour Solutions" 905 "ASA Electronics" 909 "Marines Co (South Korea)" 911 "Nautic-on" 917 "Sentinel" 929 "JL Marine Systems" 930 "Ecotronix" 944 "Zontisa Marine" 951 "EXOR International" 962 "Timbolier Industries" 963 "TJC Micro" 968 "Cox Powertrain" 969 "Blue Seas" 981 "Kobelt Manufacturing" 992 "Blue Ocean IOT" 997 "Xenta Systems" 999 "Signal K" 1004 "Ultraflex" 1008 "Lintest SmartBoat" 1011 "Soundmax" 1020 "Team Italia Marine (Onyx Marine Automation s.r.l)" 1021 "Entratech" 1022 "ITC" 1029 "The Marine Guardian" 1047 "Sonic" 1051 "ProNav" 1053 "Vetus Maxwell INC." 1056 "Lithium Pros" 1059 "Boatrax" 1062 "Marol Co ltd" 1065 "CALYPSO Instruments" 1066 "Spot Zero Water" 1069 "Lithionics Battery" 1070 "Quick-teck Electronics" 1075 "Uniden America" 1083 "Nauticoncept" 1084 "Shadow-Caster LED lighting" 1085 "Wet Sounds" 1088 "E-T-A Circuit Breakers" 1092 "Scheiber" 1100 "Smart Yachts International Limited" 1109 "Dockmate" 1114 "Bobs Machine" 1118 "L3Harris ASV" 1119 "Balmar" 1120 "Elettromedia" 1127 "Electromaax" 1140 "Across Oceans Systems" 1145 "Kiwi Yachting" 1150 "BSB Artificial Intelligence" 1151 "Orca Technologies" 1154 "TBS Electronics" 1158 "Technoton Electroics" 1160 "MG Energy Systems" 1169 "Sea Machine Robotics" 1171 "Vista Manufacturing" 1183 "Zipwake" 1186 "Sailmon" 1192 "Airmoniq Pro Kft" 1194 "Sierra Marine" 1200 "Xinuo Information Technology (Xiamen)" 1218 "Septentrio" 1233 "NKE Marine Electronics" 1238 "SuperTrack Aps" 1239 "Honda Electronics" 1245 "Raritan Engineering" 1249 "Integrated Power Solutions AG" 1260 "Interactive Technologies" 1283 "LTG-Tech" 1299 "Energy Solutions (UK)" 1300 "WATT Fuel Cell" 1302 "Pro Mainer" 1305 "Dragonfly Energy" 1306 "Koden Electronics" 1311 "Humphree" 1316 "Hinkley Yachts" 1317 "Global Marine Management GmbH (GMM)" 1320 "Triskel Marine" 1330 "Warwick Control Technologies" 1331 "Dolphin Charger" 1337 "Barnacle Systems" 1348 "Radian IoT" 1353 "Ocean LED Marine" 1359 "BluNav" 1361 "OVA (Nantong Saiyang Electronics Co., Ltd)" 1368 "RAD Propulsion" 1369 "Electric Yacht" 1372 "Elco Motor Yachts" 1384 "Tecnoseal Foundry S.r.l" 1385 "Pro Charging Systems" 1389 "EVEX" 1398 "Gobius Sensor Technology" 1403 "Arco Marine" 1408 "Lenco Marine" 1413 "Naocontrol" 1417 "Revatek" 1438 "Aeolionics" 1439 "PredictWind" 1440 "Egis Mobile Electric" 1445 "Starboard Yacht Group" 1446 "Roswell Marine" 1451 "ePropulsion (Guangdong ePropulsion Technology Ltd.)" 1452 "Micro-Air" 1453 "Vital Battery" 1458 "Ride Controller" 1460 "Tocaro Blue" 1461 "Vanquish Yachts" 1471 "FT Technologies" 1478 "Alps Alpine" 1481 "E-Force Marine" 1482 "CMC Marine" 1483 "Nanjing Sandemarine Information Technology" 1850 "Teleflex Marine (SeaStar Solutions)" 1851 "Raymarine" 1852 "Navionics" 1853 "Japan Radio" 1854 "Northstar Technologies" 1855 "Furuno" 1856 "Trimble" 1857 "Simrad" 1858 "Litton" 1859 "Kvasar" 1860 "MMP" 1861 "Vector Cantech" 1862 "Yamaha Marine" 1863 "Faria Instruments" ;
VAL_ 2650734848 Industry_Code 0 "Global" 1 "Highway" 2 "Agriculture" 3 "Construction" 4 "Marine Industry" 5 "Industrial" ;
VAL_ 2650734848 SBAS_mode 0 "Automatic" 1 "Manual" ;
VAL_ 2650734848 SBAS_satellite 0 "120" 1 "121" 2 "122" 3 "123" 4 "124" 5 "125" 6 "126" 7 "127" 8 "128" 9 "129" 10 "130" 11 "131" 12 "132" 13 "133" 14 "134" 15 "135" 16 "136" 17 "137" 18 "138" ;
VAL_ 2650734848 Manufacturer_Code 69 "ARKS Enterprises" 78 "FW Murphy/Enovation Controls" 80 "Twin Disc" 85 "Kohler Power Systems" 88 "Hemisphere GPS" 135 "Airmar" 137 "Maretron" 140 "Lowrance" 144 "Mercury Marine" 147 "Nautibus Electronic" 148 "Blue Water Data" 154 "Westerbeke" 157 "ISSPRO" 161 "Offshore Systems (UK)" 163 "Evinrude/BRP" 165 "CPAC Systems" 168 "Xantrex Technology" 169 "Marlin Technologies" 172 "Yanmar Marine" 174 "Volvo Penta" 176 "Carling Technologies Inc. (Moritz Aerospace)" 185 "Beede Instruments" 192 "Floscan Instrument" 193 "Nobeltec" 198 "Mystic Valley Communications" 199 "Actia" 201 "Disenos Y Technologia" 211 "Digital Switching Systems" 215 "Xintex/Atena" 224 "EMMI NETWORK" 228 "ZF" 229 "Garmin" 233 "Yacht Monitoring Solutions" 235 "Sailormade Marine Telemetry/Tetra Technology" 243 "Eride" 257 "Honda Motor" 272 "Groco" 273 "Actisense" 274 "Amphenol LTW Technology" 275 "Navico" 283 "Hamilton Jet" 285 "Sea Recovery" 286 "Coelmo SRL Italy" 295 "BEP Marine" 304 "Empir Bus" 305 "NovAtel" 306 "Sleipner Motor" 307 "MBW Technologies" 315 "ICOM" 328 "Qwerty" 329 "Dief" 341 "Boening Automationstechnologie" 345 "Korean Maritime University" 351 "Thrane and Thrane" 355 "Mastervolt" 356 "Fischer Panda Generators" 358 "Victron Energy" 370 "Rolls Royce Marine" 373 "Electronic Design" 374 "Northern Lights" 378 "Glendinning" 381 "B & G" 384 "Rose Point Navigation Systems" 385 "Johnson Outdoors Marine Electronics Inc Geonav" 394 "Capi 2" 396 "Beyond Measure" 400 "Livorsi Marine" 404 "ComNav" 409 "Chetco" 419 "Fusion Electronics" 421 "Standard Horizon" 422 "True Heading" 426 "Egersund Marine Electronics" 427 "em-trak Marine Electronics" 431 "Tohatsu Co, JP" 437 "Digital Yacht" 438 "Comar Systems Limited" 440 "Cummins" 443 "VDO (aka Continental-Corporation)" 451 "Parker Hannifin aka Village Marine Tech" 459 "Alltek Marine Electronics" 460 "SAN GIORGIO S.E.I.N" 466 "Veethree Electronics & Marine" 470 "SI-TEX Marine Electronics" 471 "Sea Cross Marine" 475 "GME aka Standard Communications" 476 "Humminbird Marine Electronics" 478 "Ocean Sat" 481 "Chetco Digital Instruments" 493 "Watcheye" 499 "Lcj Capteurs" 502 "Attwood Marine" 503 "Naviop S.R.L." 504 "Vesper Marine" 510 "Marinesoft" 513 "Simarine" 517 "NoLand Engineering" 518 "Transas USA" 529 "National Instruments Korea" 530 "National Marine Electronics Association" 532 "Onwa Marine" 540 "Webasto" 571 "Marinecraft (South Korea)" 573 "McMurdo Group aka Orolia" 578 "Advansea" 579 "KVH" 580 "San Jose Technology" 583 "Yacht Control" 586 "Suzuki Motor" 591 "US Coast Guard" 595 "Ship Module aka Customware" 600 "Aquatic AV" 605 "Aventics" 606 "Intellian" 612 "SamwonIT" 614 "Arlt Tecnologies" 637 "Bavaria Yachts" 641 "Diverse Yacht Services" 644 "Wema U.S.A dba KUS" 658 "Shenzhen Jiuzhou Himunication" 688 "Rockford" 699 "Harman International" 704 "JL Audio" 708 "Lars Thrane" 715 "Autonnic" 717 "Yacht Devices" 734 "REAP Systems" 735 "AEM Performance Electronics" 739 "LxNav" 741 "Littelfuse, Inc (formerly Carling Technologies)" 743 "DaeMyung" 744 "Woosung" 748 "ISOTTA IFRA srl" 773 "Clarion US" 776 "HMI Systems" 777 "Ocean Signal" 778 "Seakeeper" 781 "Poly Planar" 785 "Fischer Panda DE" 795 "Broyda Industries" 796 "Canadian Automotive" 797 "Tides Marine" 798 "Lumishore" 799 "Still Water Designs and Audio" 802 "BJ Technologies (Beneteau)" 803 "Gill Sensors" 811 "Blue Water Desalination" 815 "FLIR" 824 "Undheim Systems" 826 "Lewmar" 838 "TeamSurv" 844 "Fell Marine" 847 "Oceanvolt" 862 "Prospec" 868 "Data Panel" 890 "L3 Technologies" 894 "Rhodan Marine Systems" 896 "Nexfour Solutions" 905 "ASA Electronics" 909 "Marines Co (South Korea)" 911 "Nautic-on" 917 "Sentinel" 929 "JL Marine Systems" 930 "Ecotronix" 944 "Zontisa Marine" 951 "EXOR International" 962 "Timbolier Industries" 963 "TJC Micro" 968 "Cox Powertrain" 969 "Blue Seas" 981 "Kobelt Manufacturing" 992 "Blue Ocean IOT" 997 "Xenta Systems" 999 "Signal K" 1004 "Ultraflex" 1008 "Lintest SmartBoat" 1011 "Soundmax" 1020 "Team Italia Marine (Onyx Marine Automation s.r.l)" 1021 "Entratech" 1022 "ITC" 1029 "The Marine Guardian" 1047 "Sonic" 1051 "ProNav" 1053 "Vetus Maxwell INC." 1056 "Lithium Pros" 1059 "Boatrax" 1062 "Marol Co ltd" 1065 "CALYPSO Instruments" 1066 "Spot Zero Water" 1069 "Lithionics Battery" 1070 "Quick-teck Electronics" 1075 "Uniden America" 1083 "Nauticoncept" 1084 "Shadow-Caster LED lighting" 1085 "Wet Sounds" 1088 "E-T-A Circuit Breakers" 1092 "Scheiber" 1100 "Smart Yachts International Limited" 1109 "Dockmate" 1114 "Bobs Machine" 1118 "L3Harris ASV" 1119 "Balmar" 1120 "Elettromedia" 1127 "Electromaax" 1140 "Across Oceans Systems" 1145 "Kiwi Yachting" 1150 "BSB Artificial Intelligence" 1151 "Orca Technologies" 1154 "TBS Electronics" 1158 "Technoton Electroics" 1160 "MG Energy Systems" 1169 "Sea Machine Robotics" 1171 "Vista Manufacturing" 1183 "Zipwake" 1186 "Sailmon" 1192 "Airmoniq Pro Kft" 1194 "Sierra Marine" 1200 "Xinuo Information Technology (Xiamen)" 1218 "Septentrio" 1233 "NKE Marine Electronics" 1238 "SuperTrack Aps" 1239 "Honda Electronics" 1245 "Raritan Engineering" 1249 "Integrated Power Solutions AG" 1260 "Interactive Technologies" 1283 "LTG-Tech" 1299 "Energy Solutions (UK)" 1300 "WATT Fuel Cell" 1302 "Pro Mainer" 1305 "Dragonfly Energy" 1306 "Koden Electronics" 1311 "Humphree" 1316 "Hinkley Yachts" 1317 "Global Marine Management GmbH (GMM)" 1320 "Triskel Marine" 1330 "Warwick Control Technologies" 1331 "Dolphin Charger" 1337 "Barnacle Systems" 1348 "Radian IoT" 1353 "Ocean LED Marine" 1359 "BluNav" 1361 "OVA (Nantong Saiyang Electronics Co., Ltd)" 1368 "RAD Propulsion" 1369 "Electric Yacht" 1372 "Elco Motor Yachts" 1384 "Tecnoseal Foundry S.r.l" 1385 "Pro Charging Systems" 1389 "EVEX" 1398 "Gobius Sensor Technology" 1403 "Arco Marine" 1408 "Lenco Marine" 1413 "Naocontrol" 1417 "Revatek" 1438 "Aeolionics" 1439 "PredictWind" 1440 "Egis Mobile Electric" 1445 "Starboard Yacht Group" 1446 "Roswell Marine" 1451 "ePropulsion (Guangdong ePropulsion Technology Ltd.)" 1452 "Micro-Air" 1453 "Vital Battery" 1458 "Ride Controller" 1460 "Tocaro Blue" 1461 "Vanquish Yachts" 1471 "FT Technologies" 1478 "Alps Alpine" 1481 "E-Force Marine" 1482 "CMC Marine" 1483 "Nanjing Sandemarine Information Technology" 1850 "Teleflex Marine (SeaStar Solutions)" 1851 "Raymarine" 1852 "Navionics" 1853 "Japan Radio" 1854 "Northstar Technologies" 1855 "Furuno" 1856 "Trimble" 1857 "Simrad" 1858 "Litton" 1859 "Kvasar" 1860 "MMP" 1861 "Vector Cantech" 1862 "Yamaha Marine" 1863 "Faria Instruments" ;
VAL_ 2650734848 Industry_Code 0 "Global" 1 "Highway" 2 "Agriculture" 3 "Construction" 4 "Marine Industry" 5 "Industrial" ;
VAL_ 2650734848 Manufacturer_Code 69 "ARKS Enterprises" 78 "FW Murphy/Enovation Controls" 80 "Twin Disc" 85 "Kohler Power Systems" 88 "Hemisphere GPS" 135 "Airmar" 137 "Maretron" 140 "Lowrance" 144 "Mercury Marine" 147 "Nautibus Electronic" 148 "Blue Water Data" 154 "Westerbeke" 157 "ISSPRO" 161 "Offshore Systems (UK)" 163 "Evinrude/BRP" 165 "CPAC Systems" 168 "Xantrex Technology" 169 "Marlin Technologies" 172 "Yanmar Marine" 174 "Volvo Penta" 176 "Carling Technologies Inc. (Moritz Aerospace)" 185 "Beede Instruments" 192 "Floscan Instrument" 193 "Nobeltec" 198 "Mystic Valley Communications" 199 "Actia" 201 "Disenos Y Technologia" 211 "Digital Switching Systems" 215 "Xintex/Atena" 224 "EMMI NETWORK" 228 "ZF" 229 "Garmin" 233 "Yacht Monitoring Solutions" 235 "Sailormade Marine Telemetry/Tetra Technology" 243 "Eride" 257 "Honda Motor" 272 "Groco" 273 "Actisense" 274 "Amphenol LTW Technology" 275 "Navico" 283 "Hamilton Jet" 285 "Sea Recovery" 286 "Coelmo SRL Italy" 295 "BEP Marine" 304 "Empir Bus" 305 "NovAtel" 306 "Sleipner Motor" 307 "MBW Technologies" 315 "ICOM" 328 "Qwerty" 329 "Dief" 341 "Boening Automationstechnologie" 345 "Korean Maritime University" 351 "Thrane and Thrane" 355 "Mastervolt" 356 "Fischer Panda Generators" 358 "Victron Energy" 370 "Rolls Royce Marine" 373 "Electronic Design" 374 "Northern Lights" 378 "Glendinning" 381 "B & G" 384 "Rose Point Navigation Systems" 385 "Johnson Outdoors Marine Electronics Inc Geonav" 394 "Capi 2" 396 "Beyond Measure" 400 "Livorsi Marine" 404 "ComNav" 409 "Chetco" 419 "Fusion Electronics" 421 "Standard Horizon" 422 "True Heading" 426 "Egersund Marine Electronics" 427 "em-trak Marine Electronics" 431 "Tohatsu Co, JP" 437 "Digital Yacht" 438 "Comar Systems Limited" 440 "Cummins" 443 "VDO (aka Continental-Corporation)" 451 "Parker Hannifin aka Village Marine Tech" 459 "Alltek Marine Electronics" 460 "SAN GIORGIO S.E.I.N" 466 "Veethree Electronics & Marine" 470 "SI-TEX Marine Electronics" 471 "Sea Cross Marine" 475 "GME aka Standard Communications" 476 "Humminbird Marine Electronics" 478 "Ocean Sat" 481 "Chetco Digital Instruments" 493 "Watcheye" 499 "Lcj Capteurs" 502 "Attwood Marine" 503 "Naviop S.R.L." 504 "Vesper Marine" 510 "Marinesoft" 513 "Simarine" 517 "NoLand Engineering" 518 "Transas USA" 529 "National Instruments Korea" 530 "National Marine Electronics Association" 532 "Onwa Marine" 540 "Webasto" 571 "Marinecraft (South Korea)" 573 "McMurdo Group aka Orolia" 578 "Advansea" 579 "KVH" 580 "San Jose Technology" 583 "Yacht Control" 586 "Suzuki Motor" 591 "US Coast Guard" 595 "Ship Module aka Customware" 600 "Aquatic AV" 605 "Aventics" 606 "Intellian" 612 "SamwonIT" 614 "Arlt Tecnologies" 637 "Bavaria Yachts" 641 "Diverse Yacht Services" 644 "Wema U.S.A dba KUS" 658 "Shenzhen Jiuzhou Himunication" 688 "Rockford" 699 "Harman International" 704 "JL Audio" 708 "Lars Thrane" 715 "Autonnic" 717 "Yacht Devices" 734 "REAP Systems" 735 "AEM Performance Electronics" 739 "LxNav" 741 "Littelfuse, Inc (formerly Carling Technologies)" 743 "DaeMyung" 744 "Woosung" 748 "ISOTTA IFRA srl" 773 "Clarion US" 776 "HMI Systems" 777 "Ocean Signal" 778 "Seakeeper" 781 "Poly Planar" 785 "Fischer Panda DE" 795 "Broyda Industries" 796 "Canadian Automotive" 797 "Tides Marine" 798 "Lumishore" 799 "Still Water Designs and Audio" 802 "BJ Technologies (Beneteau)" 803 "Gill Sensors" 811 "Blue Water Desalination" 815 "FLIR" 824 "Undheim Systems" 826 "Lewmar" 838 "TeamSurv" 844 "Fell Marine" 847 "Oceanvolt" 862 "Prospec" 868 "Data Panel" 890 "L3 Technologies" 894 "Rhodan Marine Systems" 896 "Nexfour Solutions" 905 "ASA Electronics" 909 "Marines Co (South Korea)" 911 "Nautic-on" 917 "Sentinel" 929 "JL Marine Systems" 930 "Ecotronix" 944 "Zontisa Marine" 951 "EXOR International" 962 "Timbolier Industries" 963 "TJC Micro" 968 "Cox Powertrain" 969 "Blue Seas" 981 "Kobelt Manufacturing" 992 "Blue Ocean IOT" 997 "Xenta Systems" 999 "Signal K" 1004 "Ultraflex" 1008 "Lintest SmartBoat" 1011 "Soundmax" 1020 "Team Italia Marine (Onyx Marine Automation s.r.l)" 1021 "Entratech" 1022 "ITC" 1029 "The Marine Guardian" 1047 "Sonic" 1051 "ProNav" 1053 "Vetus Maxwell INC." 1056 "Lithium Pros" 1059 "Boatrax" 1062 "Marol Co ltd" 1065 "CALYPSO Instruments" 1066 "Spot Zero Water" 1069 "Lithionics Battery" 1070 "Quick-teck Electronics" 1075 "Uniden America" 1083 "Nauticoncept" 1084 "Shadow-Caster LED lighting" 1085 "Wet Sounds" 1088 "E-T-A Circuit Breakers" 1092 "Scheiber" 1100 "Smart Yachts International Limited" 1109 "Dockmate" 1114 "Bobs Machine" 1118 "L3Harris ASV" 1119 "Balmar" 1120 "Elettromedia" 1127 "Electromaax" 1140 "Across Oceans Systems" 1145 "Kiwi Yachting" 1150 "BSB Artificial Intelligence" 1151 "Orca Technologies" 1154 "TBS Electronics" 1158 "Technoton Electroics" 1160 "MG Energy Systems" 1169 "Sea Machine Robotics" 1171 "Vista Manufacturing" 1183 "Zipwake" 1186 "Sailmon" 1192 "Airmoniq Pro Kft" 1194 "Sierra Marine" 1200 "Xinuo Information Technology (Xiamen)" 1218 "Septentrio" 1233 "NKE Marine Electronics" 1238 "SuperTrack Aps" 1239 "Honda Electronics" 1245 "Raritan Engineering" 1249 "Integrated Power Solutions AG" 1260 "Interactive Technologies" 1283 "LTG-Tech" 1299 "Energy Solutions (UK)" 1300 "WATT Fuel Cell" 1302 "Pro Mainer" 1305 "Dragonfly Energy" 1306 "Koden Electronics" 1311 "Humphree" 1316 "Hinkley Yachts" 1317 "Global Marine Management GmbH (GMM)" 1320 "Triskel Marine" 1330 "Warwick Control Technologies" 1331 "Dolphin Charger" 1337 "Barnacle Systems" 1348 "Radian IoT" 1353 "Ocean LED Marine" 1359 "BluNav" 1361 "OVA (Nantong Saiyang Electronics Co., Ltd)" 1368 "RAD Propulsion" 1369 "Electric Yacht" 1372 "Elco Motor Yachts" 1384 "Tecnoseal Foundry S.r.l" 1385 "Pro Charging Systems" 1389 "EVEX" 1398 "Gobius Sensor Technology" 1403 "Arco Marine" 1408 "Lenco Marine" 1413 "Naocontrol" 1417 "Revatek" 1438 "Aeolionics" 1439 "PredictWind" 1440 "Egis Mobile Electric" 1445 "Starboard Yacht Group" 1446 "Roswell Marine" 1451 "ePropulsion (Guangdong ePropulsion Technology Ltd.)" 1452 "Micro-Air" 1453 "Vital Battery" 1458 "Ride Controller" 1460 "Tocaro Blue" 1461 "Vanquish Yachts" 1471 "FT Technologies" 1478 "Alps Alpine" 1481 "E-Force Marine" 1482 "CMC Marine" 1483 "Nanjing Sandemarine Information Technology" 1850 "Teleflex Marine (SeaStar Solutions)" 1851 "Raymarine" 1852 "Navionics" 1853 "Japan Radio" 1854 "Northstar Technologies" 1855 "Furuno" 1856 "Trimble" 1857 "Simrad" 1858 "Litton" 1859 "Kvasar" 1860 "MMP" 1861 "Vector Cantech" 1862 "Yamaha Marine" 1863 "Faria Instruments" ;
VAL_ 2650734848 Industry_Code 0 "Global" 1 "Highway" 2 "Agriculture" 3 "Construction" 4 "Marine Industry" 5 "Industrial" ;
VAL_ 2583626240 Manufacturer_Code 69 "ARKS Enterprises" 78 "FW Murphy/Enovation Controls" 80 "Twin Disc" 85 "Kohler Power Systems" 88 "Hemisphere GPS" 135 "Airmar" 137 "Maretron" 140 "Lowrance" 144 "Mercury Marine" 147 "Nautibus Electronic" 148 "Blue Water Data" 154 "Westerbeke" 157 "ISSPRO" 161 "Offshore Systems (UK)" 163 "Evinrude/BRP" 165 "CPAC Systems" 168 "Xantrex Technology" 169 "Marlin Technologies" 172 "Yanmar Marine" 174 "Volvo Penta" 176 "Carling Technologies Inc. (Moritz Aerospace)" 185 "Beede Instruments" 192 "Floscan Instrument" 193 "Nobeltec" 198 "Mystic Valley Communications" 199 "Actia" 201 "Disenos Y Technologia" 211 "Digital Switching Systems" 215 "Xintex/Atena" 224 "EMMI NETWORK" 228 "ZF" 229 "Garmin" 233 "Yacht Monitoring Solutions" 235 "Sailormade Marine Telemetry/Tetra Technology" 243 "Eride" 257 "Honda Motor" 272 "Groco" 273 "Actisense" 274 "Amphenol LTW Technology" 275 "Navico" 283 "Hamilton Jet" 285 "Sea Recovery" 286 "Coelmo SRL Italy" 295 "BEP Marine" 304 "Empir Bus" 305 "NovAtel" 306 "Sleipner Motor" 307 "MBW Technologies" 315 "ICOM" 328 "Qwerty" 329 "Dief" 341 "Boening Automationstechnologie" 345 "Korean Maritime University" 351 "Thrane and Thrane" 355 "Mastervolt" 356 "Fischer Panda Generators" 358 "Victron Energy" 370 "Rolls Royce Marine" 373 "Electronic Design" 374 "Northern Lights" 378 "Glendinning" 381 "B & G" 384 "Rose Point Navigation Systems" 385 "Johnson Outdoors Marine Electronics Inc Geonav" 394 "Capi 2" 396 "Beyond Measure" 400 "Livorsi Marine" 404 "ComNav" 409 "Chetco" 419 "Fusion Electronics" 421 "Standard Horizon" 422 "True Heading" 426 "Egersund Marine Electronics" 427 "em-trak Marine Electronics" 431 "Tohatsu Co, JP" 437 "Digital Yacht" 438 "Comar Systems Limited" 440 "Cummins" 443 "VDO (aka Continental-Corporation)" 451 "Parker Hannifin aka Village Marine Tech" 459 "Alltek Marine Electronics" 460 "SAN GIORGIO S.E.I.N" 466 "Veethree Electronics & Marine" 470 "SI-TEX Marine Electronics" 471 "Sea Cross Marine" 475 "GME aka Standard Communications" 476 "Humminbird Marine Electronics" 478 "Ocean Sat" 481 "Chetco Digital Instruments" 493 "Watcheye" 499 "Lcj Capteurs" 502 "Attwood Marine" 503 "Naviop S.R.L." 504 "Vesper Marine" 510 "Marinesoft" 513 "Simarine" 517 "NoLand Engineering" 518 "Transas USA" 529 "National Instruments Korea" 530 "National Marine Electronics Association" 532 "Onwa Marine" 540 "Webasto" 571 "Marinecraft (South Korea)" 573 "McMurdo Group aka Orolia" 578 "Advansea" 579 "KVH" 580 "San Jose Technology" 583 "Yacht Control" 586 "Suzuki Motor" 591 "US Coast Guard" 595 "Ship Module aka Customware" 600 "Aquatic AV" 605 "Aventics" 606 "Intellian" 612 "SamwonIT" 614 "Arlt Tecnologies" 637 "Bavaria Yachts" 641 "Diverse Yacht Services" 644 "Wema U.S.A dba KUS" 658 "Shenzhen Jiuzhou Himunication" 688 "Rockford" 699 "Harman International" 704 "JL Audio" 708 "Lars Thrane" 715 "Autonnic" 717 "Yacht Devices" 734 "REAP Systems" 735 "AEM Performance Electronics" 739 "LxNav" 741 "Littelfuse, Inc (formerly Carling Technologies)" 743 "DaeMyung" 744 "Woosung" 748 "ISOTTA IFRA srl" 773 "Clarion US" 776 "HMI Systems" 777 "Ocean Signal" 778 "Seakeeper" 781 "Poly Planar" 785 "Fischer Panda DE" 795 "Broyda Industries" 796 "Canadian Automotive" 797 "Tides Marine" 798 "Lumishore" 799 "Still Water Designs and Audio" 802 "BJ Technologies (Beneteau)" 803 "Gill Sensors" 811 "Blue Water Desalination" 815 "FLIR" 824 "Undheim Systems" 826 "Lewmar" 838 "TeamSurv" 844 "Fell Marine" 847 "Oceanvolt" 862 "Prospec" 868 "Data Panel" 890 "L3 Technologies" 894 "Rhodan Marine Systems" 896 "Nexfour Solutions" 905 "ASA Electronics" 909 "Marines Co (South Korea)" 911 "Nautic-on" 917 "Sentinel" 929 "JL Marine Systems" 930 "Ecotronix" 944 "Zontisa Marine" 951 "EXOR International" 962 "Timbolier Industries" 963 "TJC Micro" 968 "Cox Powertrain" 969 "Blue Seas" 981 "Kobelt Manufacturing" 992 "Blue Ocean IOT" 997 "Xenta Systems" 999 "Signal K" 1004 "Ultraflex" 1008 "Lintest SmartBoat" 1011 "Soundmax" 1020 "Team Italia Marine (Onyx Marine Automation s.r.l)" 1021 "Entratech" 1022 "ITC" 1029 "The Marine Guardian" 1047 "Sonic" 1051 "ProNav" 1053 "Vetus Maxwell INC." 1056 "Lithium Pros" 1059 "Boatrax" 1062 "Marol Co ltd" 1065 "CALYPSO Instruments" 1066 "Spot Zero Water" 1069 "Lithionics Battery" 1070 "Quick-teck Electronics" 1075 "Uniden America" 1083 "Nauticoncept" 1084 "Shadow-Caster LED lighting" 1085 "Wet Sounds" 1088 "E-T-A Circuit Breakers" 1092 "Scheiber" 1100 "Smart Yachts International Limited" 1109 "Dockmate" 1114 "Bobs Machine" 1118 "L3Harris ASV" 1119 "Balmar" 1120 "Elettromedia" 1127 "Electromaax" 1140 "Across Oceans Systems" 1145 "Kiwi Yachting" 1150 "BSB Artificial Intelligence" 1151 "Orca Technologies" 1154 "TBS Electronics" 1158 "Technoton Electroics" 1160 "MG Energy Systems" 1169 "Sea Machine Robotics" 1171 "Vista Manufacturing" 1183 "Zipwake" 1186 "Sailmon" 1192 "Airmoniq Pro Kft" 1194 "Sierra Marine" 1200 "Xinuo Information Technology (Xiamen)" 1218 "Septentrio" 1233 "NKE Marine Electronics" 1238 "SuperTrack Aps" 1239 "Honda Electronics" 1245 "Raritan Engineering" 1249 "Integrated Power Solutions AG" 1260 "Interactive Technologies" 1283 "LTG-Tech" 1299 "Energy Solutions (UK)" 1300 "WATT Fuel Cell" 1302 "Pro Mainer" 1305 "Dragonfly Energy" 1306 "Koden Electronics" 1311 "Humphree" 1316 "Hinkley Yachts" 1317 "Global Marine Management GmbH (GMM)" 1320 "Triskel Marine" 1330 "Warwick Control Technologies" 1331 "Dolphin Charger" 1337 "Barnacle Systems" 1348 "Radian IoT" 1353 "Ocean LED Marine" 1359 "BluNav" 1361 "OVA (Nantong Saiyang Electronics Co., Ltd)" 1368 "RAD Propulsion" 1369 "Electric Yacht" 1372 "Elco Motor Yachts" 1384 "Tecnoseal Foundry S.r.l" 1385 "Pro Charging Systems" 1389 "EVEX" 1398 "Gobius Sensor Technology" 1403 "Arco Marine" 1408 "Lenco Marine" 1413 "Naocontrol" 1417 "Revatek" 1438 "Aeolionics" 1439 "PredictWind" 1440 "Egis Mobile Electric" 1445 "Starboard Yacht Group" 1446 "Roswell Marine" 1451 "ePropulsion (Guangdong ePropulsion Technology Ltd.)" 1452 "Micro-Air" 1453 "Vital Battery" 1458 "Ride Controller" 1460 "Tocaro Blue" 1461 "Vanquish Yachts" 1471 "FT Technologies" 1478 "Alps Alpine" 1481 "E-Force Marine" 1482 "CMC Marine" 1483 "Nanjing Sandemarine Information Technology" 1850 "Teleflex Marine (SeaStar Solutions)" 1851 "Raymarine" 1852 "Navionics" 1853 "Japan Radio" 1854 "Northstar Technologies" 1855 "Furuno" 1856 "Trimble" 1857 "Simrad" 1858 "Litton" 1859 "Kvasar" 1860 "MMP" 1861 "Vector Cantech" 1862 "Yamaha Marine" 1863 "Faria Instruments" ;
VAL_ 2583626240 Industry_Code 0 "Global" 1 "Highway" 2 "Agriculture" 3 "Construction" 4 "Marine Industry" 5 "Industrial" ;
VAL_ 2650735104 Manufacturer_Code 69 "ARKS Enterprises" 78 "FW Murphy/Enovation Controls" 80 "Twin Disc" 85 "Kohler Power Systems" 88 "Hemisphere GPS" 135 "Airmar" 137 "Maretron" 140 "Lowrance" 144 "Mercury Marine" 147 "Nautibus Electronic" 148 "Blue Water Data" 154 "Westerbeke" 157 "ISSPRO" 161 "Offshore Systems (UK)" 163 "Evinrude/BRP" 165 "CPAC Systems" 168 "Xantrex Technology" 169 "Marlin Technologies" 172 "Yanmar Marine" 174 "Volvo Penta" 176 "Carling Technologies Inc. (Moritz Aerospace)" 185 "Beede Instruments" 192 "Floscan Instrument" 193 "Nobeltec" 198 "Mystic Valley Communications" 199 "Actia" 201 "Disenos Y Technologia" 211 "Digital Switching Systems" 215 "Xintex/Atena" 224 "EMMI NETWORK" 228 "ZF" 229 "Garmin" 233 "Yacht Monitoring Solutions" 235 "Sailormade Marine Telemetry/Tetra Technology" 243 "Eride" 257 "Honda Motor" 272 "Groco" 273 "Actisense" 274 "Amphenol LTW Technology" 275 "Navico" 283 "Hamilton Jet" 285 "Sea Recovery" 286 "Coelmo SRL Italy" 295 "BEP Marine" 304 "Empir Bus" 305 "NovAtel" 306 "Sleipner Motor" 307 "MBW Technologies" 315 "ICOM" 328 "Qwerty" 329 "Dief" 341 "Boening Automationstechnologie" 345 "Korean Maritime University" 351 "Thrane and Thrane" 355 "Mastervolt" 356 "Fischer Panda Generators" 358 "Victron Energy" 370 "Rolls Royce Marine" 373 "Electronic Design" 374 "Northern Lights" 378 "Glendinning" 381 "B & G" 384 "Rose Point Navigation Systems" 385 "Johnson Outdoors Marine Electronics Inc Geonav" 394 "Capi 2" 396 "Beyond Measure" 400 "Livorsi Marine" 404 "ComNav" 409 "Chetco" 419 "Fusion Electronics" 421 "Standard Horizon" 422 "True Heading" 426 "Egersund Marine Electronics" 427 "em-trak Marine Electronics" 431 "Tohatsu Co, JP" 437 "Digital Yacht" 438 "Comar Systems Limited" 440 "Cummins" 443 "VDO (aka Continental-Corporation)" 451 "Parker Hannifin aka Village Marine Tech" 459 "Alltek Marine Electronics" 460 "SAN GIORGIO S.E.I.N" 466 "Veethree Electronics & Marine" 470 "SI-TEX Marine Electronics" 471 "Sea Cross Marine" 475 "GME aka Standard Communications" 476 "Humminbird Marine Electronics" 478 "Ocean Sat" 481 "Chetco Digital Instruments" 493 "Watcheye" 499 "Lcj Capteurs" 502 "Attwood Marine" 503 "Naviop S.R.L." 504 "Vesper Marine" 510 "Marinesoft" 513 "Simarine" 517 "NoLand Engineering" 518 "Transas USA" 529 "National Instruments Korea" 530 "National Marine Electronics Association" 532 "Onwa Marine" 540 "Webasto" 571 "Marinecraft (South Korea)" 573 "McMurdo Group aka Orolia" 578 "Advansea" 579 "KVH" 580 "San Jose Technology" 583 "Yacht Control" 586 "Suzuki Motor" 591 "US Coast Guard" 595 "Ship Module aka Customware" 600 "Aquatic AV" 605 "Aventics" 606 "Intellian" 612 "SamwonIT" 614 "Arlt Tecnologies" 637 "Bavaria Yachts" 641 "Diverse Yacht Services" 644 "Wema U.S.A dba KUS" 658 "Shenzhen Jiuzhou Himunication" 688 "Rockford" 699 "Harman International" 704 "JL Audio" 708 "Lars Thrane" 715 "Autonnic" 717 "Yacht Devices" 734 "REAP Systems" 735 "AEM Performance Electronics" 739 "LxNav" 741 "Littelfuse, Inc (formerly Carling Technologies)" 743 "DaeMyung" 744 "Woosung" 748 "ISOTTA IFRA srl" 773 "Clarion US" 776 "HMI Systems" 777 "Ocean Signal" 778 "Seakeeper" 781 "Poly Planar" 785 "Fischer Panda DE" 795 "Broyda Industries" 796 "Canadian Automotive" 797 "Tides Marine" 798 "Lumishore" 799 "Still Water Designs and Audio" 802 "BJ Technologies (Beneteau)" 803 "Gill Sensors" 811 "Blue Water Desalination" 815 "FLIR" 824 "Undheim Systems" 826 "Lewmar" 838 "TeamSurv" 844 "Fell Marine" 847 "Oceanvolt" 862 "Prospec" 868 "Data Panel" 890 "L3 Technologies" 894 "Rhodan Marine Systems" 896 "Nexfour Solutions" 905 "ASA Electronics" 909 "Marines Co (South Korea)" 911 "Nautic-on" 917 "Sentinel" 929 "JL Marine Systems" 930 "Ecotronix" 944 "Zontisa Marine" 951 "EXOR International" 962 "Timbolier Industries" 963 "TJC Micro" 968 "Cox Powertrain" 969 "Blue Seas" 981 "Kobelt Manufacturing" 992 "Blue Ocean IOT" 997 "Xenta Systems" 999 "Signal K" 1004 "Ultraflex" 1008 "Lintest SmartBoat" 1011 "Soundmax" 1020 "Team Italia Marine (Onyx Marine Automation s.r.l)" 1021 "Entratech" 1022 "ITC" 1029 "The Marine Guardian" 1047 "Sonic" 1051 "ProNav" 1053 "Vetus Maxwell INC." 1056 "Lithium Pros" 1059 "Boatrax" 1062 "Marol Co ltd" 1065 "CALYPSO Instruments" 1066 "Spot Zero Water" 1069 "Lithionics Battery" 1070 "Quick-teck Electronics" 1075 "Uniden America" 1083 "Nauticoncept" 1084 "Shadow-Caster LED lighting" 1085 "Wet Sounds" 1088 "E-T-A Circuit Breakers" 1092 "Scheiber" 1100 "Smart Yachts International Limited" 1109 "Dockmate" 1114 "Bobs Machine" 1118 "L3Harris ASV" 1119 "Balmar" 1120 "Elettromedia" 1127 "Electromaax" 1140 "Across Oceans Systems" 1145 "Kiwi Yachting" 1150 "BSB Artificial Intelligence" 1151 "Orca Technologies" 1154 "TBS Electronics" 1158 "Technoton Electroics" 1160 "MG Energy Systems" 1169 "Sea Machine Robotics" 1171 "Vista Manufacturing" 1183 "Zipwake" 1186 "Sailmon" 1192 "Airmoniq Pro Kft" 1194 "Sierra Marine" 1200 "Xinuo Information Technology (Xiamen)" 1218 "Septentrio" 1233 "NKE Marine Electronics" 1238 "SuperTrack Aps" 1239 "Honda Electronics" 1245 "Raritan Engineering" 1249 "Integrated Power Solutions AG" 1260 "Interactive Technologies" 1283 "LTG-Tech" 1299 "Energy Solutions (UK)" 1300 "WATT Fuel Cell" 1302 "Pro Mainer" 1305 "Dragonfly Energy" 1306 "Koden Electronics" 1311 "Humphree" 1316 "Hinkley Yachts" 1317 "Global Marine Management GmbH (GMM)" 1320 "Triskel Marine" 1330 "Warwick Control Technologies" 1331 "Dolphin Charger" 1337 "Barnacle Systems" 1348 "Radian IoT" 1353 "Ocean LED Marine" 1359 "BluNav" 1361 "OVA (Nantong Saiyang Electronics Co., Ltd)" 1368 "RAD Propulsion" 1369 "Electric Yacht" 1372 "Elco Motor Yachts" 1384 "Tecnoseal Foundry S.r.l" 1385 "Pro Charging Systems" 1389 "EVEX" 1398 "Gobius Sensor Technology" 1403 "Arco Marine" 1408 "Lenco Marine" 1413 "Naocontrol" 1417 "Revatek" 1438 "Aeolionics" 1439 "PredictWind" 1440 "Egis Mobile Electric" 1445 "Starboard Yacht Group" 1446 "Roswell Marine" 1451 "ePropulsion (Guangdong ePropulsion Technology Ltd.)" 1452 "Micro-Air" 1453 "Vital Battery" 1458 "Ride Controller" 1460 "Tocaro Blue" 1461 "Vanquish Yachts" 1471 "FT Technologies" 1478 "Alps Alpine" 1481 "E-Force Marine" 1482 "CMC Marine" 1483 "Nanjing Sandemarine Information Technology" 1850 "Teleflex Marine (SeaStar Solutions)" 1851 "Raymarine" 1852 "Navionics" 1853 "Japan Radio" 1854 "Northstar Technologies" 1855 "Furuno" 1856 "Trimble" 1857 "Simrad" 1858 "Litton" 1859 "Kvasar" 1860 "MMP" 1861 "Vector Cantech" 1862 "Yamaha Marine" 1863 "Faria Instruments" ;
VAL_ 2650735104 Industry_Code 0 "Global" 1 "Highway" 2 "Agriculture" 3 "Construction" 4 "Marine Industry" 5 "Industrial" ;
VAL_ 2650735104 Manufacturer_Code 69 "ARKS Enterprises" 78 "FW Murphy/Enovation Controls" 80 "Twin Disc" 85 "Kohler Power Systems" 88 "Hemisphere GPS" 135 "Airmar" 137 "Maretron" 140 "Lowrance" 144 "Mercury Marine" 147 "Nautibus Electronic" 148 "Blue Water Data" 154 "Westerbeke" 157 "ISSPRO" 161 "Offshore Systems (UK)" 163 "Evinrude/BRP" 165 "CPAC Systems" 168 "Xantrex Technology" 169 "Marlin Technologies" 172 "Yanmar Marine" 174 "Volvo Penta" 176 "Carling Technologies Inc. (Moritz Aerospace)" 185 "Beede Instruments" 192 "Floscan Instrument" 193 "Nobeltec" 198 "Mystic Valley Communications" 199 "Actia" 201 "Disenos Y Technologia" 211 "Digital Switching Systems" 215 "Xintex/Atena" 224 "EMMI NETWORK" 228 "ZF" 229 "Garmin" 233 "Yacht Monitoring Solutions" 235 "Sailormade Marine Telemetry/Tetra Technology" 243 "Eride" 257 "Honda Motor" 272 "Groco" 273 "Actisense" 274 "Amphenol LTW Technology" 275 "Navico" 283 "Hamilton Jet" 285 "Sea Recovery" 286 "Coelmo SRL Italy" 295 "BEP Marine" 304 "Empir Bus" 305 "NovAtel" 306 "Sleipner Motor" 307 "MBW Technologies" 315 "ICOM" 328 "Qwerty" 329 "Dief" 341 "Boening Automationstechnologie" 345 "Korean Maritime University" 351 "Thrane and Thrane" 355 "Mastervolt" 356 "Fischer Panda Generators" 358 "Victron Energy" 370 "Rolls Royce Marine" 373 "Electronic Design" 374 "Northern Lights" 378 "Glendinning" 381 "B & G" 384 "Rose Point Navigation Systems" 385 "Johnson Outdoors Marine Electronics Inc Geonav" 394 "Capi 2" 396 "Beyond Measure" 400 "Livorsi Marine" 404 "ComNav" 409 "Chetco" 419 "Fusion Electronics" 421 "Standard Horizon" 422 "True Heading" 426 "Egersund Marine Electronics" 427 "em-trak Marine Electronics" 431 "Tohatsu Co, JP" 437 "Digital Yacht" 438 "Comar Systems Limited" 440 "Cummins" 443 "VDO (aka Continental-Corporation)" 451 "Parker Hannifin aka Village Marine Tech" 459 "Alltek Marine Electronics" 460 "SAN GIORGIO S.E.I.N" 466 "Veethree Electronics & Marine" 470 "SI-TEX Marine Electronics" 471 "Sea Cross Marine" 475 "GME aka Standard Communications" 476 "Humminbird Marine Electronics" 478 "Ocean Sat" 481 "Chetco Digital Instruments" 493 "Watcheye" 499 "Lcj Capteurs" 502 "Attwood Marine" 503 "Naviop S.R.L." 504 "Vesper Marine" 510 "Marinesoft" 513 "Simarine" 517 "NoLand Engineering" 518 "Transas USA" 529 "National Instruments Korea" 530 "National Marine Electronics Association" 532 "Onwa Marine" 540 "Webasto" 571 "Marinecraft (South Korea)" 573 "McMurdo Group aka Orolia" 578 "Advansea" 579 "KVH" 580 "San Jose Technology" 583 "Yacht Control" 586 "Suzuki Motor" 591 "US Coast Guard" 595 "Ship Module aka Customware" 600 "Aquatic AV" 605 "Aventics" 606 "Intellian" 612 "SamwonIT" 614 "Arlt Tecnologies" 637 "Bavaria Yachts" 641 "Diverse Yacht Services" 644 "Wema U.S.A dba KUS" 658 "Shenzhen Jiuzhou Himunication" 688 "Rockford" 699 "Harman International" 704 "JL Audio" 708 "Lars Thrane" 715 "Autonnic" 717 "Yacht Devices" 734 "REAP Systems" 735 "AEM Performance Electronics" 739 "LxNav" 741 "Littelfuse, Inc (formerly Carling Technologies)" 743 "DaeMyung" 744 "Woosung" 748 "ISOTTA IFRA srl" 773 "Clarion US" 776 "HMI Systems" 777 "Ocean Signal" 778 "Seakeeper" 781 "Poly Planar" 785 "Fischer Panda DE" 795 "Broyda Industries" 796 "Canadian Automotive" 797 "Tides Marine" 798 "Lumishore" 799 "Still Water Designs and Audio" 802 "BJ Technologies (Beneteau)" 803 "Gill Sensors" 811 "Blue Water Desalination" 815 "FLIR" 824 "Undheim Systems" 826 "Lewmar" 838 "TeamSurv" 844 "Fell Marine" 847 "Oceanvolt" 862 "Prospec" 868 "Data Panel" 890 "L3 Technologies" 894 "Rhodan Marine Systems" 896 "Nexfour Solutions" 905 "ASA Electronics" 909 "Marines Co (South Korea)" 911 "Nautic-on" 917 "Sentinel" 929 "JL Marine Systems" 930 "Ecotronix" 944 "Zontisa Marine" 951 "EXOR International" 962 "Timbolier Industries" 963 "TJC Micro" 968 "Cox Powertrain" 969 "Blue Seas" 981 "Kobelt Manufacturing" 992 "Blue Ocean IOT" 997 "Xenta Systems" 999 "Signal K" 1004 "Ultraflex" 1008 "Lintest SmartBoat" 1011 "Soundmax" 1020 "Team Italia Marine (Onyx Marine Automation s.r.l)" 1021 "Entratech" 1022 "ITC" 1029 "The Marine Guardian" 1047 "Sonic" 1051 "ProNav" 1053 "Vetus Maxwell INC." 1056 "Lithium Pros" 1059 "Boatrax" 1062 "Marol Co ltd" 1065 "CALYPSO Instruments" 1066 "Spot Zero Water" 1069 "Lithionics Battery" 1070 "Quick-teck Electronics" 1075 "Uniden America" 1083 "Nauticoncept" 1084 "Shadow-Caster LED lighting" 1085 "Wet Sounds" 1088 "E-T-A Circuit Breakers" 1092 "Scheiber" 1100 "Smart Yachts International Limited" 1109 "Dockmate" 1114 "Bobs Machine" 1118 "L3Harris ASV" 1119 "Balmar" 1120 "Elettromedia" 1127 "Electromaax" 1140 "Across Oceans Systems" 1145 "Kiwi Yachting" 1150 "BSB Artificial Intelligence" 1151 "Orca Technologies" 1154 "TBS Electronics" 1158 "Technoton Electroics" 1160 "MG Energy Systems" 1169 "Sea Machine Robotics" 1171 "Vista Manufacturing" 1183 "Zipwake" 1186 "Sailmon" 1192 "Airmoniq Pro Kft" 1194 "Sierra Marine" 1200 "Xinuo Information Technology (Xiamen)" 1218 "Septentrio" 1233 "NKE Marine Electronics" 1238 "SuperTrack Aps" 1239 "Honda Electronics" 1245 "Raritan Engineering" 1249 "Integrated Power Solutions AG" 1260 "Interactive Technologies" 1283 "LTG-Tech" 1299 "Energy Solutions (UK)" 1300 "WATT Fuel Cell" 1302 "Pro Mainer" 1305 "Dragonfly Energy" 1306 "Koden Electronics" 1311 "Humphree" 1316 "Hinkley Yachts" 1317 "Global Marine Management GmbH (GMM)" 1320 "Triskel Marine" 1330 "Warwick Control Technologies" 1331 "Dolphin Charger" 1337 "Barnacle Systems" 1348 "Radian IoT" 1353 "Ocean LED Marine" 1359 "BluNav" 1361 "OVA (Nantong Saiyang Electronics Co., Ltd)" 1368 "RAD Propulsion" 1369 "Electric Yacht" 1372 "Elco Motor Yachts" 1384 "Tecnoseal Foundry S.r.l" 1385 "Pro Charging Systems" 1389 "EVEX" 1398 "Gobius Sensor Technology" 1403 "Arco Marine" 1408 "Lenco Marine" 1413 "Naocontrol" 1417 "Revatek" 1438 "Aeolionics" 1439 "PredictWind" 1440 "Egis Mobile Electric" 1445 "Starboard Yacht Group" 1446 "Roswell Marine" 1451 "ePropulsion (Guangdong ePropulsion Technology Ltd.)" 1452 "Micro-Air" 1453 "Vital Battery" 1458 "Ride Controller" 1460 "Tocaro Blue" 1461 "Vanquish Yachts" 1471 "FT Technologies" 1478 "Alps Alpine" 1481 "E-Force Marine" 1482 "CMC Marine" 1483 "Nanjing Sandemarine Information Technology" 1850 "Teleflex Marine (SeaStar Solutions)" 1851 "Raymarine" 1852 "Navionics" 1853 "Japan Radio" 1854 "Northstar Technologies" 1855 "Furuno" 1856 "Trimble" 1857 "Simrad" 1858 "Litton" 1859 "Kvasar" 1860 "MMP" 1861 "Vector Cantech" 1862 "Yamaha Marine" 1863 "Faria Instruments" ;
VAL_ 2650735104 Industry_Code 0 "Global" 1 "Highway" 2 "Agriculture" 3 "Construction" 4 "Marine Industry" 5 "Industrial" ;
VAL_ 2650735104 Manufacturer_Code 69 "ARKS Enterprises" 78 "FW Murphy/Enovation Controls" 80 "Twin Disc" 85 "Kohler Power Systems" 88 "Hemisphere GPS" 135 "Airmar" 137 "Maretron" 140 "Lowrance" 144 "Mercury Marine" 147 "Nautibus Electronic" 148 "Blue Water Data" 154 "Westerbeke" 157 "ISSPRO" 161 "Offshore Systems (UK)" 163 "Evinrude/BRP" 165 "CPAC Systems" 168 "Xantrex Technology" 169 "Marlin Technologies" 172 "Yanmar Marine" 174 "Volvo Penta" 176 "Carling Technologies Inc. (Moritz Aerospace)" 185 "Beede Instruments" 192 "Floscan Instrument" 193 "Nobeltec" 198 "Mystic Valley Communications" 199 "Actia" 201 "Disenos Y Technologia" 211 "Digital Switching Systems" 215 "Xintex/Atena" 224 "EMMI NETWORK" 228 "ZF" 229 "Garmin" 233 "Yacht Monitoring Solutions" 235 "Sailormade Marine Telemetry/Tetra Technology" 243 "Eride" 257 "Honda Motor" 272 "Groco" 273 "Actisense" 274 "Amphenol LTW Technology" 275 "Navico" 283 "Hamilton Jet" 285 "Sea Recovery" 286 "Coelmo SRL Italy" 295 "BEP Marine" 304 "Empir Bus" 305 "NovAtel" 306 "Sleipner Motor" 307 "MBW Technologies" 315 "ICOM" 328 "Qwerty" 329 "Dief" 341 "Boening Automationstechnologie" 345 "Korean Maritime University" 351 "Thrane and Thrane" 355 "Mastervolt" 356 "Fischer Panda Generators" 358 "Victron Energy" 370 "Rolls Royce Marine" 373 "Electronic Design" 374 "Northern Lights" 378 "Glendinning" 381 "B & G" 384 "Rose Point Navigation Systems" 385 "Johnson Outdoors Marine Electronics Inc Geonav" 394 "Capi 2" 396 "Beyond Measure" 400 "Livorsi Marine" 404 "ComNav" 409 "Chetco" 419 "Fusion Electronics" 421 "Standard Horizon" 422 "True Heading" 426 "Egersund Marine Electronics" 427 "em-trak Marine Electronics" 431 "Tohatsu Co, JP" 437 "Digital Yacht" 438 "Comar Systems Limited" 440 "Cummins" 443 "VDO (aka Continental-Corporation)" 451 "Parker Hannifin aka Village Marine Tech" 459 "Alltek Marine Electronics" 460 "SAN GIORGIO S.E.I.N" 466 "Veethree Electronics & Marine" 470 "SI-TEX Marine Electronics" 471 "Sea Cross Marine" 475 "GME aka Standard Communications" 476 "Humminbird Marine Electronics" 478 "Ocean Sat" 481 "Chetco Digital Instruments" 493 "Watcheye" 499 "Lcj Capteurs" 502 "Attwood Marine" 503 "Naviop S.R.L." 504 "Vesper Marine" 510 "Marinesoft" 513 "Simarine" 517 "NoLand Engineering" 518 "Transas USA" 529 "National Instruments Korea" 530 "National Marine Electronics Association" 532 "Onwa Marine" 540 "Webasto" 571 "Marinecraft (South Korea)" 573 "McMurdo Group aka Orolia" 578 "Advansea" 579 "KVH" 580 "San Jose Technology" 583 "Yacht Control" 586 "Suzuki Motor" 591 "US Coast Guard" 595 "Ship Module aka Customware" 600 "Aquatic AV" 605 "Aventics" 606 "Intellian" 612 "SamwonIT" 614 "Arlt Tecnologies" 637 "Bavaria Yachts" 641 "Diverse Yacht Services" 644 "Wema U.S.A dba KUS" 658 "Shenzhen Jiuzhou Himunication" 688 "Rockford" 699 "Harman International" 704 "JL Audio" 708 "Lars Thrane" 715 "Autonnic" 717 "Yacht Devices" 734 "REAP Systems" 735 "AEM Performance Electronics" 739 "LxNav" 741 "Littelfuse, Inc (formerly Carling Technologies)" 743 "DaeMyung" 744 "Woosung" 748 "ISOTTA IFRA srl" 773 "Clarion US" 776 "HMI Systems" 777 "Ocean Signal" 778 "Seakeeper" 781 "Poly Planar" 785 "Fischer Panda DE" 795 "Broyda Industries" 796 "Canadian Automotive" 797 "Tides Marine" 798 "Lumishore" 799 "Still Water Designs and Audio" 802 "BJ Technologies (Beneteau)" 803 "Gill Sensors" 811 "Blue Water Desalination" 815 "FLIR" 824 "Undheim Systems" 826 "Lewmar" 838 "TeamSurv" 844 "Fell Marine" 847 "Oceanvolt" 862 "Prospec" 868 "Data Panel" 890 "L3 Technologies" 894 "Rhodan Marine Systems" 896 "Nexfour Solutions" 905 "ASA Electronics" 909 "Marines Co (South Korea)" 911 "Nautic-on" 917 "Sentinel" 929 "JL Marine Systems" 930 "Ecotronix" 944 "Zontisa Marine" 951 "EXOR International" 962 "Timbolier Industries" 963 "TJC Micro" 968 "Cox Powertrain" 969 "Blue Seas" 981 "Kobelt Manufacturing" 992 "Blue Ocean IOT" 997 "Xenta Systems" 999 "Signal K" 1004 "Ultraflex" 1008 "Lintest SmartBoat" 1011 "Soundmax" 1020 "Team Italia Marine (Onyx Marine Automation s.r.l)" 1021 "Entratech" 1022 "ITC" 1029 "The Marine Guardian" 1047 "Sonic" 1051 "ProNav" 1053 "Vetus Maxwell INC." 1056 "Lithium Pros" 1059 "Boatrax" 1062 "Marol Co ltd" 1065 "CALYPSO Instruments" 1066 "Spot Zero Water" 1069 "Lithionics Battery" 1070 "Quick-teck Electronics" 1075 "Uniden America" 1083 "Nauticoncept" 1084 "Shadow-Caster LED lighting" 1085 "Wet Sounds" 1088 "E-T-A Circuit Breakers" 1092 "Scheiber" 1100 "Smart Yachts International Limited" 1109 "Dockmate" 1114 "Bobs Machine" 1118 "L3Harris ASV" 1119 "Balmar" 1120 "Elettromedia" 1127 "Electromaax" 1140 "Across Oceans Systems" 1145 "Kiwi Yachting" 1150 "BSB Artificial Intelligence" 1151 "Orca Technologies" 1154 "TBS Electronics" 1158 "Technoton Electroics" 1160 "MG Energy Systems" 1169 "Sea Machine Robotics" 1171 "Vista Manufacturing" 1183 "Zipwake" 1186 "Sailmon" 1192 "Airmoniq Pro Kft" 1194 "Sierra Marine" 1200 "Xinuo Information Technology (Xiamen)" 1218 "Septentrio" 1233 "NKE Marine Electronics" 1238 "SuperTrack Aps" 1239 "Honda Electronics" 1245 "Raritan Engineering" 1249 "Integrated Power Solutions AG" 1260 "Interactive Technologies" 1283 "LTG-Tech" 1299 "Energy Solutions (UK)" 1300 "WATT Fuel Cell" 1302 "Pro Mainer" 1305 "Dragonfly Energy" 1306 "Koden Electronics" 1311 "Humphree" 1316 "Hinkley Yachts" 1317 "Global Marine Management GmbH (GMM)" 1320 "Triskel Marine" 1330 "Warwick Control Technologies" 1331 "Dolphin Charger" 1337 "Barnacle Systems" 1348 "Radian IoT" 1353 "Ocean LED Marine" 1359 "BluNav" 1361 "OVA (Nantong Saiyang Electronics Co., Ltd)" 1368 "RAD Propulsion" 1369 "Electric Yacht" 1372 "Elco Motor Yachts" 1384 "Tecnoseal Foundry S.r.l" 1385 "Pro Charging Systems" 1389 "EVEX" 1398 "Gobius Sensor Technology" 1403 "Arco Marine" 1408 "Lenco Marine" 1413 "Naocontrol" 1417 "Revatek" 1438 "Aeolionics" 1439 "PredictWind" 1440 "Egis Mobile Electric" 1445 "Starboard Yacht Group" 1446 "Roswell Marine" 1451 "ePropulsion (Guangdong ePropulsion Technology Ltd.)" 1452 "Micro-Air" 1453 "Vital Battery" 1458 "Ride Controller" 1460 "Tocaro Blue" 1461 "Vanquish Yachts" 1471 "FT Technologies" 1478 "Alps Alpine" 1481 "E-Force Marine" 1482 "CMC Marine" 1483 "Nanjing Sandemarine Information Technology" 1850 "Teleflex Marine (SeaStar Solutions)" 1851 "Raymarine" 1852 "Navionics" 1853 "Japan Radio" 1854 "Northstar Technologies" 1855 "Furuno" 1856 "Trimble" 1857 "Simrad" 1858 "Litton" 1859 "Kvasar" 1860 "MMP" 1861 "Vector Cantech" 1862 "Yamaha Marine" 1863 "Faria Instruments" ;
VAL_ 2650735104 Industry_Code 0 "Global" 1 "Highway" 2 "Agriculture" 3 "Construction" 4 "Marine Industry" 5 "Industrial" ;
VAL_ 2583626240 Manufacturer_Code 69 "ARKS Enterprises" 78 "FW Murphy/Enovation Controls" 80 "Twin Disc" 85 "Kohler Power Systems" 88 "Hemisphere GPS" 135 "Airmar" 137 "Maretron" 140 "Lowrance" 144 "Mercury Marine" 147 "Nautibus Electronic" 148 "Blue Water Data" 154 "Westerbeke" 157 "ISSPRO" 161 "Offshore Systems (UK)" 163 "Evinrude/BRP" 165 "CPAC Systems" 168 "Xantrex Technology" 169 "Marlin Technologies" 172 "Yanmar Marine" 174 "Volvo Penta" 176 "Carling Technologies Inc. (Moritz Aerospace)" 185 "Beede Instruments" 192 "Floscan Instrument" 193 "Nobeltec" 198 "Mystic Valley Communications" 199 "Actia" 201 "Disenos Y Technologia" 211 "Digital Switching Systems" 215 "Xintex/Atena" 224 "EMMI NETWORK" 228 "ZF" 229 "Garmin" 233 "Yacht Monitoring Solutions" 235 "Sailormade Marine Telemetry/Tetra Technology" 243 "Eride" 257 "Honda Motor" 272 "Groco" 273 "Actisense" 274 "Amphenol LTW Technology" 275 "Navico" 283 "Hamilton Jet" 285 "Sea Recovery" 286 "Coelmo SRL Italy" 295 "BEP Marine" 304 "Empir Bus" 305 "NovAtel" 306 "Sleipner Motor" 307 "MBW Technologies" 315 "ICOM" 328 "Qwerty" 329 "Dief" 341 "Boening Automationstechnologie" 345 "Korean Maritime University" 351 "Thrane and Thrane" 355 "Mastervolt" 356 "Fischer Panda Generators" 358 "Victron Energy" 370 "Rolls Royce Marine" 373 "Electronic Design" 374 "Northern Lights" 378 "Glendinning" 381 "B & G" 384 "Rose Point Navigation Systems" 385 "Johnson Outdoors Marine Electronics Inc Geonav" 394 "Capi 2" 396 "Beyond Measure" 400 "Livorsi Marine" 404 "ComNav" 409 "Chetco" 419 "Fusion Electronics" 421 "Standard Horizon" 422 "True Heading" 426 "Egersund Marine Electronics" 427 "em-trak Marine Electronics" 431 "Tohatsu Co, JP" 437 "Digital Yacht" 438 "Comar Systems Limited" 440 "Cummins" 443 "VDO (aka Continental-Corporation)" 451 "Parker Hannifin aka Village Marine Tech" 459 "Alltek Marine Electronics" 460 "SAN GIORGIO S.E.I.N" 466 "Veethree Electronics & Marine" 470 "SI-TEX Marine Electronics" 471 "Sea Cross Marine" 475 "GME aka Standard Communications" 476 "Humminbird Marine Electronics" 478 "Ocean Sat" 481 "Chetco Digital Instruments" 493 "Watcheye" 499 "Lcj Capteurs" 502 "Attwood Marine" 503 "Naviop S.R.L." 504 "Vesper Marine" 510 "Marinesoft" 513 "Simarine" 517 "NoLand Engineering" 518 "Transas USA" 529 "National Instruments Korea" 530 "National Marine Electronics Association" 532 "Onwa Marine" 540 "Webasto" 571 "Marinecraft (South Korea)" 573 "McMurdo Group aka Orolia" 578 "Advansea" 579 "KVH" 580 "San Jose Technology" 583 "Yacht Control" 586 "Suzuki Motor" 591 "US Coast Guard" 595 "Ship Module aka Customware" 600 "Aquatic AV" 605 "Aventics" 606 "Intellian" 612 "SamwonIT" 614 "Arlt Tecnologies" 637 "Bavaria Yachts" 641 "Diverse Yacht Services" 644 "Wema U.S.A dba KUS" 658 "Shenzhen Jiuzhou Himunication" 688 "Rockford" 699 "Harman International" 704 "JL Audio" 708 "Lars Thrane" 715 "Autonnic" 717 "Yacht Devices" 734 "REAP Systems" 735 "AEM Performance Electronics" 739 "LxNav" 741 "Littelfuse, Inc (formerly Carling Technologies)" 743 "DaeMyung" 744 "Woosung" 748 "ISOTTA IFRA srl" 773 "Clarion US" 776 "HMI Systems" 777 "Ocean Signal" 778 "Seakeeper" 781 "Poly Planar" 785 "Fischer Panda DE" 795 "Broyda Industries" 796 "Canadian Automotive" 797 "Tides Marine" 798 "Lumishore" 799 "Still Water Designs and Audio" 802 "BJ Technologies (Beneteau)" 803 "Gill Sensors" 811 "Blue Water Desalination" 815 "FLIR" 824 "Undheim Systems" 826 "Lewmar" 838 "TeamSurv" 844 "Fell Marine" 847 "Oceanvolt" 862 "Prospec" 868 "Data Panel" 890 "L3 Technologies" 894 "Rhodan Marine Systems" 896 "Nexfour Solutions" 905 "ASA Electronics" 909 "Marines Co (South Korea)" 911 "Nautic-on" 917 "Sentinel" 929 "JL Marine Systems" 930 "Ecotronix" 944 "Zontisa Marine" 951 "EXOR International" 962 "Timbolier Industries" 963 "TJC Micro" 968 "Cox Powertrain" 969 "Blue Seas" 981 "Kobelt Manufacturing" 992 "Blue Ocean IOT" 997 "Xenta Systems" 999 "Signal K" 1004 "Ultraflex" 1008 "Lintest SmartBoat" 1011 "Soundmax" 1020 "Team Italia Marine (Onyx Marine Automation s.r.l)" 1021 "Entratech" 1022 "ITC" 1029 "The Marine Guardian" 1047 "Sonic" 1051 "ProNav" 1053 "Vetus Maxwell INC." 1056 "Lithium Pros" 1059 "Boatrax" 1062 "Marol Co ltd" 1065 "CALYPSO Instruments" 1066 "Spot Zero Water" 1069 "Lithionics Battery" 1070 "Quick-teck Electronics" 1075 "Uniden America" 1083 "Nauticoncept" 1084 "Shadow-Caster LED lighting" 1085 "Wet Sounds" 1088 "E-T-A Circuit Breakers" 1092 "Scheiber" 1100 "Smart Yachts International Limited" 1109 "Dockmate" 1114 "Bobs Machine" 1118 "L3Harris ASV" 1119 "Balmar" 1120 "Elettromedia" 1127 "Electromaax" 1140 "Across Oceans Systems" 1145 "Kiwi Yachting" 1150 "BSB Artificial Intelligence" 1151 "Orca Technologies" 1154 "TBS Electronics" 1158 "Technoton Electroics" 1160 "MG Energy Systems" 1169 "Sea Machine Robotics" 1171 "Vista Manufacturing" 1183 "Zipwake" 1186 "Sailmon" 1192 "Airmoniq Pro Kft" 1194 "Sierra Marine" 1200 "Xinuo Information Technology (Xiamen)" 1218 "Septentrio" 1233 "NKE Marine Electronics" 1238 "SuperTrack Aps" 1239 "Honda Electronics" 1245 "Raritan Engineering" 1249 "Integrated Power Solutions AG" 1260 "Interactive Technologies" 1283 "LTG-Tech" 1299 "Energy Solutions (UK)" 1300 "WATT Fuel Cell" 1302 "Pro Mainer" 1305 "Dragonfly Energy" 1306 "Koden Electronics" 1311 "Humphree" 1316 "Hinkley Yachts" 1317 "Global Marine Management GmbH (GMM)" 1320 "Triskel Marine" 1330 "Warwick Control Technologies" 1331 "Dolphin Charger" 1337 "Barnacle Systems" 1348 "Radian IoT" 1353 "Ocean LED Marine" 1359 "BluNav" 1361 "OVA (Nantong Saiyang Electronics Co., Ltd)" 1368 "RAD Propulsion" 1369 "Electric Yacht" 1372 "Elco Motor Yachts" 1384 "Tecnoseal Foundry S.r.l" 1385 "Pro Charging Systems" 1389 "EVEX" 1398 "Gobius Sensor Technology" 1403 "Arco Marine" 1408 "Lenco Marine" 1413 "Naocontrol" 1417 "Revatek" 1438 "Aeolionics" 1439 "PredictWind" 1440 "Egis Mobile Electric" 1445 "Starboard Yacht Group" 1446 "Roswell Marine" 1451 "ePropulsion (Guangdong ePropulsion Technology Ltd.)" 1452 "Micro-Air" 1453 "Vital Battery" 1458 "Ride Controller" 1460 "Tocaro Blue" 1461 "Vanquish Yachts" 1471 "FT Technologies" 1478 "Alps Alpine" 1481 "E-Force Marine" 1482 "CMC Marine" 1483 "Nanjing Sandemarine Information Technology" 1850 "Teleflex Marine (SeaStar Solutions)" 1851 "Raymarine" 1852 "Navionics" 1853 "Japan Radio" 1854 "Northstar Technologies" 1855 "Furuno" 1856 "Trimble" 1857 "Simrad" 1858 "Litton" 1859 "Kvasar" 1860 "MMP" 1861 "Vector Cantech" 1862 "Yamaha Marine" 1863 "Faria Instruments" ;
VAL_ 2583626240 Industry_Code 0 "Global" 1 "Highway" 2 "Agriculture" 3 "Construction" 4 "Marine Industry" 5 "Industrial" ;
VAL_ 2583626496 Manufacturer_Code 69 "ARKS Enterprises" 78 "FW Murphy/Enovation Controls" 80 "Twin Disc" 85 "Kohler Power Systems" 88 "Hemisphere GPS" 135 "Airmar" 137 "Maretron" 140 "Lowrance" 144 "Mercury Marine" 147 "Nautibus Electronic" 148 "Blue Water Data" 154 "Westerbeke" 157 "ISSPRO" 161 "Offshore Systems (UK)" 163 "Evinrude/BRP" 165 "CPAC Systems" 168 "Xantrex Technology" 169 "Marlin Technologies" 172 "Yanmar Marine" 174 "Volvo Penta" 176 "Carling Technologies Inc. (Moritz Aerospace)" 185 "Beede Instruments" 192 "Floscan Instrument" 193 "Nobeltec" 198 "Mystic Valley Communications" 199 "Actia" 201 "Disenos Y Technologia" 211 "Digital Switching Systems" 215 "Xintex/Atena" 224 "EMMI NETWORK" 228 "ZF" 229 "Garmin" 233 "Yacht Monitoring Solutions" 235 "Sailormade Marine Telemetry/Tetra Technology" 243 "Eride" 257 "Honda Motor" 272 "Groco" 273 "Actisense" 274 "Amphenol LTW Technology" 275 "Navico" 283 "Hamilton Jet" 285 "Sea Recovery" 286 "Coelmo SRL Italy" 295 "BEP Marine" 304 "Empir Bus" 305 "NovAtel" 306 "Sleipner Motor" 307 "MBW Technologies" 315 "ICOM" 328 "Qwerty" 329 "Dief" 341 "Boening Automationstechnologie" 345 "Korean Maritime University" 351 "Thrane and Thrane" 355 "Mastervolt" 356 "Fischer Panda Generators" 358 "Victron Energy" 370 "Rolls Royce Marine" 373 "Electronic Design" 374 "Northern Lights" 378 "Glendinning" 381 "B & G" 384 "Rose Point Navigation Systems" 385 "Johnson Outdoors Marine Electronics Inc Geonav" 394 "Capi 2" 396 "Beyond Measure" 400 "Livorsi Marine" 404 "ComNav" 409 "Chetco" 419 "Fusion Electronics" 421 "Standard Horizon" 422 "True Heading" 426 "Egersund Marine Electronics" 427 "em-trak Marine Electronics" 431 "Tohatsu Co, JP" 437 "Digital Yacht" 438 "Comar Systems Limited" 440 "Cummins" 443 "VDO (aka Continental-Corporation)" 451 "Parker Hannifin aka Village Marine Tech" 459 "Alltek Marine Electronics" 460 "SAN GIORGIO S.E.I.N" 466 "Veethree Electronics & Marine" 470 "SI-TEX Marine Electronics" 471 "Sea Cross Marine" 475 "GME aka Standard Communications" 476 "Humminbird Marine Electronics" 478 "Ocean Sat" 481 "Chetco Digital Instruments" 493 "Watcheye" 499 "Lcj Capteurs" 502 "Attwood Marine" 503 "Naviop S.R.L." 504 "Vesper Marine" 510 "Marinesoft" 513 "Simarine" 517 "NoLand Engineering" 518 "Transas USA" 529 "National Instruments Korea" 530 "National Marine Electronics Association" 532 "Onwa Marine" 540 "Webasto" 571 "Marinecraft (South Korea)" 573 "McMurdo Group aka Orolia" 578 "Advansea" 579 "KVH" 580 "San Jose Technology" 583 "Yacht Control" 586 "Suzuki Motor" 591 "US Coast Guard" 595 "Ship Module aka Customware" 600 "Aquatic AV" 605 "Aventics" 606 "Intellian" 612 "SamwonIT" 614 "Arlt Tecnologies" 637 "Bavaria Yachts" 641 "Diverse Yacht Services" 644 "Wema U.S.A dba KUS" 658 "Shenzhen Jiuzhou Himunication" 688 "Rockford" 699 "Harman International" 704 "JL Audio" 708 "Lars Thrane" 715 "Autonnic" 717 "Yacht Devices" 734 "REAP Systems" 735 "AEM Performance Electronics" 739 "LxNav" 741 "Littelfuse, Inc (formerly Carling Technologies)" 743 "DaeMyung" 744 "Woosung" 748 "ISOTTA IFRA srl" 773 "Clarion US" 776 "HMI Systems" 777 "Ocean Signal" 778 "Seakeeper" 781 "Poly Planar" 785 "Fischer Panda DE" 795 "Broyda Industries" 796 "Canadian Automotive" 797 "Tides Marine" 798 "Lumishore" 799 "Still Water Designs and Audio" 802 "BJ Technologies (Beneteau)" 803 "Gill Sensors" 811 "Blue Water Desalination" 815 "FLIR" 824 "Undheim Systems" 826 "Lewmar" 838 "TeamSurv" 844 "Fell Marine" 847 "Oceanvolt" 862 "Prospec" 868 "Data Panel" 890 "L3 Technologies" 894 "Rhodan Marine Systems" 896 "Nexfour Solutions" 905 "ASA Electronics" 909 "Marines Co (South Korea)" 911 "Nautic-on" 917 "Sentinel" 929 "JL Marine Systems" 930 "Ecotronix" 944 "Zontisa Marine" 951 "EXOR International" 962 "Timbolier Industries" 963 "TJC Micro" 968 "Cox Powertrain" 969 "Blue Seas" 981 "Kobelt Manufacturing" 992 "Blue Ocean IOT" 997 "Xenta Systems" 999 "Signal K" 1004 "Ultraflex" 1008 "Lintest SmartBoat" 1011 "Soundmax" 1020 "Team Italia Marine (Onyx Marine Automation s.r.l)" 1021 "Entratech" 1022 "ITC" 1029 "The Marine Guardian" 1047 "Sonic" 1051 "ProNav" 1053 "Vetus Maxwell INC." 1056 "Lithium Pros" 1059 "Boatrax" 1062 "Marol Co ltd" 1065 "CALYPSO Instruments" 1066 "Spot Zero Water" 1069 "Lithionics Battery" 1070 "Quick-teck Electronics" 1075 "Uniden America" 1083 "Nauticoncept" 1084 "Shadow-Caster LED lighting" 1085 "Wet Sounds" 1088 "E-T-A Circuit Breakers" 1092 "Scheiber" 1100 "Smart Yachts International Limited" 1109 "Dockmate" 1114 "Bobs Machine" 1118 "L3Harris ASV" 1119 "Balmar" 1120 "Elettromedia" 1127 "Electromaax" 1140 "Across Oceans Systems" 1145 "Kiwi Yachting" 1150 "BSB Artificial Intelligence" 1151 "Orca Technologies" 1154 "TBS Electronics" 1158 "Technoton Electroics" 1160 "MG Energy Systems" 1169 "Sea Machine Robotics" 1171 "Vista Manufacturing" 1183 "Zipwake" 1186 "Sailmon" 1192 "Airmoniq Pro Kft" 1194 "Sierra Marine" 1200 "Xinuo Information Technology (Xiamen)" 1218 "Septentrio" 1233 "NKE Marine Electronics" 1238 "SuperTrack Aps" 1239 "Honda Electronics" 1245 "Raritan Engineering" 1249 "Integrated Power Solutions AG" 1260 "Interactive Technologies" 1283 "LTG-Tech" 1299 "Energy Solutions (UK)" 1300 "WATT Fuel Cell" 1302 "Pro Mainer" 1305 "Dragonfly Energy" 1306 "Koden Electronics" 1311 "Humphree" 1316 "Hinkley Yachts" 1317 "Global Marine Management GmbH (GMM)" 1320 "Triskel Marine" 1330 "Warwick Control Technologies" 1331 "Dolphin Charger" 1337 "Barnacle Systems" 1348 "Radian IoT" 1353 "Ocean LED Marine" 1359 "BluNav" 1361 "OVA (Nantong Saiyang Electronics Co., Ltd)" 1368 "RAD Propulsion" 1369 "Electric Yacht" 1372 "Elco Motor Yachts" 1384 "Tecnoseal Foundry S.r.l" 1385 "Pro Charging Systems" 1389 "EVEX" 1398 "Gobius Sensor Technology" 1403 "Arco Marine" 1408 "Lenco Marine" 1413 "Naocontrol" 1417 "Revatek" 1438 "Aeolionics" 1439 "PredictWind" 1440 "Egis Mobile Electric" 1445 "Starboard Yacht Group" 1446 "Roswell Marine" 1451 "ePropulsion (Guangdong ePropulsion Technology Ltd.)" 1452 "Micro-Air" 1453 "Vital Battery" 1458 "Ride Controller" 1460 "Tocaro Blue" 1461 "Vanquish Yachts" 1471 "FT Technologies" 1478 "Alps Alpine" 1481 "E-Force Marine" 1482 "CMC Marine" 1483 "Nanjing Sandemarine Information Technology" 1850 "Teleflex Marine (SeaStar Solutions)" 1851 "Raymarine" 1852 "Navionics" 1853 "Japan Radio" 1854 "Northstar Technologies" 1855 "Furuno" 1856 "Trimble" 1857 "Simrad" 1858 "Litton" 1859 "Kvasar" 1860 "MMP" 1861 "Vector Cantech" 1862 "Yamaha Marine" 1863 "Faria Instruments" ;
VAL_ 2583626496 Industry_Code 0 "Global" 1 "Highway" 2 "Agriculture" 3 "Construction" 4 "Marine Industry" 5 "Industrial" ;
VAL_ 2650735360 Manufacturer_Code 69 "ARKS Enterprises" 78 "FW Murphy/Enovation Controls" 80 "Twin Disc" 85 "Kohler Power Systems" 88 "Hemisphere GPS" 135 "Airmar" 137 "Maretron" 140 "Lowrance" 144 "Mercury Marine" 147 "Nautibus Electronic" 148 "Blue Water Data" 154 "Westerbeke" 157 "ISSPRO" 161 "Offshore Systems (UK)" 163 "Evinrude/BRP" 165 "CPAC Systems" 168 "Xantrex Technology" 169 "Marlin Technologies" 172 "Yanmar Marine" 174 "Volvo Penta" 176 "Carling Technologies Inc. (Moritz Aerospace)" 185 "Beede Instruments" 192 "Floscan Instrument" 193 "Nobeltec" 198 "Mystic Valley Communications" 199 "Actia" 201 "Disenos Y Technologia" 211 "Digital Switching Systems" 215 "Xintex/Atena" 224 "EMMI NETWORK" 228 "ZF" 229 "Garmin" 233 "Yacht Monitoring Solutions" 235 "Sailormade Marine Telemetry/Tetra Technology" 243 "Eride" 257 "Honda Motor" 272 "Groco" 273 "Actisense" 274 "Amphenol LTW Technology" 275 "Navico" 283 "Hamilton Jet" 285 "Sea Recovery" 286 "Coelmo SRL Italy" 295 "BEP Marine" 304 "Empir Bus" 305 "NovAtel" 306 "Sleipner Motor" 307 "MBW Technologies" 315 "ICOM" 328 "Qwerty" 329 "Dief" 341 "Boening Automationstechnologie" 345 "Korean Maritime University" 351 "Thrane and Thrane" 355 "Mastervolt" 356 "Fischer Panda Generators" 358 "Victron Energy" 370 "Rolls Royce Marine" 373 "Electronic Design" 374 "Northern Lights" 378 "Glendinning" 381 "B & G" 384 "Rose Point Navigation Systems" 385 "Johnson Outdoors Marine Electronics Inc Geonav" 394 "Capi 2" 396 "Beyond Measure" 400 "Livorsi Marine" 404 "ComNav" 409 "Chetco" 419 "Fusion Electronics" 421 "Standard Horizon" 422 "True Heading" 426 "Egersund Marine Electronics" 427 "em-trak Marine Electronics" 431 "Tohatsu Co, JP" 437 "Digital Yacht" 438 "Comar Systems Limited" 440 "Cummins" 443 "VDO (aka Continental-Corporation)" 451 "Parker Hannifin aka Village Marine Tech" 459 "Alltek Marine Electronics" 460 "SAN GIORGIO S.E.I.N" 466 "Veethree Electronics & Marine" 470 "SI-TEX Marine Electronics" 471 "Sea Cross Marine" 475 "GME aka Standard Communications" 476 "Humminbird Marine Electronics" 478 "Ocean Sat" 481 "Chetco Digital Instruments" 493 "Watcheye" 499 "Lcj Capteurs" 502 "Attwood Marine" 503 "Naviop S.R.L." 504 "Vesper Marine" 510 "Marinesoft" 513 "Simarine" 517 "NoLand Engineering" 518 "Transas USA" 529 "National Instruments Korea" 530 "National Marine Electronics Association" 532 "Onwa Marine" 540 "Webasto" 571 "Marinecraft (South Korea)" 573 "McMurdo Group aka Orolia" 578 "Advansea" 579 "KVH" 580 "San Jose Technology" 583 "Yacht Control" 586 "Suzuki Motor" 591 "US Coast Guard" 595 "Ship Module aka Customware" 600 "Aquatic AV" 605 "Aventics" 606 "Intellian" 612 "SamwonIT" 614 "Arlt Tecnologies" 637 "Bavaria Yachts" 641 "Diverse Yacht Services" 644 "Wema U.S.A dba KUS" 658 "Shenzhen Jiuzhou Himunication" 688 "Rockford" 699 "Harman International" 704 "JL Audio" 708 "Lars Thrane" 715 "Autonnic" 717 "Yacht Devices" 734 "REAP Systems" 735 "AEM Performance Electronics" 739 "LxNav" 741 "Littelfuse, Inc (formerly Carling Technologies)" 743 "DaeMyung" 744 "Woosung" 748 "ISOTTA IFRA srl" 773 "Clarion US" 776 "HMI Systems" 777 "Ocean Signal" 778 "Seakeeper" 781 "Poly Planar" 785 "Fischer Panda DE" 795 "Broyda Industries" 796 "Canadian Automotive" 797 "Tides Marine" 798 "Lumishore" 799 "Still Water Designs and Audio" 802 "BJ Technologies (Beneteau)" 803 "Gill Sensors" 811 "Blue Water Desalination" 815 "FLIR" 824 "Undheim Systems" 826 "Lewmar" 838 "TeamSurv" 844 "Fell Marine" 847 "Oceanvolt" 862 "Prospec" 868 "Data Panel" 890 "L3 Technologies" 894 "Rhodan Marine Systems" 896 "Nexfour Solutions" 905 "ASA Electronics" 909 "Marines Co (South Korea)" 911 "Nautic-on" 917 "Sentinel" 929 "JL Marine Systems" 930 "Ecotronix" 944 "Zontisa Marine" 951 "EXOR International" 962 "Timbolier Industries" 963 "TJC Micro" 968 "Cox Powertrain" 969 "Blue Seas" 981 "Kobelt Manufacturing" 992 "Blue Ocean IOT" 997 "Xenta Systems" 999 "Signal K" 1004 "Ultraflex" 1008 "Lintest SmartBoat" 1011 "Soundmax" 1020 "Team Italia Marine (Onyx Marine Automation s.r.l)" 1021 "Entratech" 1022 "ITC" 1029 "The Marine Guardian" 1047 "Sonic" 1051 "ProNav" 1053 "Vetus Maxwell INC." 1056 "Lithium Pros" 1059 "Boatrax" 1062 "Marol Co ltd" 1065 "CALYPSO Instruments" 1066 "Spot Zero Water" 1069 "Lithionics Battery" 1070 "Quick-teck Electronics" 1075 "Uniden America" 1083 "Nauticoncept" 1084 "Shadow-Caster LED lighting" 1085 "Wet Sounds" 1088 "E-T-A Circuit Breakers" 1092 "Scheiber" 1100 "Smart Yachts International Limited" 1109 "Dockmate" 1114 "Bobs Machine" 1118 "L3Harris ASV" 1119 "Balmar" 1120 "Elettromedia" 1127 "Electromaax" 1140 "Across Oceans Systems" 1145 "Kiwi Yachting" 1150 "BSB Artificial Intelligence" 1151 "Orca Technologies" 1154 "TBS Electronics" 1158 "Technoton Electroics" 1160 "MG Energy Systems" 1169 "Sea Machine Robotics" 1171 "Vista Manufacturing" 1183 "Zipwake" 1186 "Sailmon" 1192 "Airmoniq Pro Kft" 1194 "Sierra Marine" 1200 "Xinuo Information Technology (Xiamen)" 1218 "Septentrio" 1233 "NKE Marine Electronics" 1238 "SuperTrack Aps" 1239 "Honda Electronics" 1245 "Raritan Engineering" 1249 "Integrated Power Solutions AG" 1260 "Interactive Technologies" 1283 "LTG-Tech" 1299 "Energy Solutions (UK)" 1300 "WATT Fuel Cell" 1302 "Pro Mainer" 1305 "Dragonfly Energy" 1306 "Koden Electronics" 1311 "Humphree" 1316 "Hinkley Yachts" 1317 "Global Marine Management GmbH (GMM)" 1320 "Triskel Marine" 1330 "Warwick Control Technologies" 1331 "Dolphin Charger" 1337 "Barnacle Systems" 1348 "Radian IoT" 1353 "Ocean LED Marine" 1359 "BluNav" 1361 "OVA (Nantong Saiyang Electronics Co., Ltd)" 1368 "RAD Propulsion" 1369 "Electric Yacht" 1372 "Elco Motor Yachts" 1384 "Tecnoseal Foundry S.r.l" 1385 "Pro Charging Systems" 1389 "EVEX" 1398 "Gobius Sensor Technology" 1403 "Arco Marine" 1408 "Lenco Marine" 1413 "Naocontrol" 1417 "Revatek" 1438 "Aeolionics" 1439 "PredictWind" 1440 "Egis Mobile Electric" 1445 "Starboard Yacht Group" 1446 "Roswell Marine" 1451 "ePropulsion (Guangdong ePropulsion Technology Ltd.)" 1452 "Micro-Air" 1453 "Vital Battery" 1458 "Ride Controller" 1460 "Tocaro Blue" 1461 "Vanquish Yachts" 1471 "FT Technologies" 1478 "Alps Alpine" 1481 "E-Force Marine" 1482 "CMC Marine" 1483 "Nanjing Sandemarine Information Technology" 1850 "Teleflex Marine (SeaStar Solutions)" 1851 "Raymarine" 1852 "Navionics" 1853 "Japan Radio" 1854 "Northstar Technologies" 1855 "Furuno" 1856 "Trimble" 1857 "Simrad" 1858 "Litton" 1859 "Kvasar" 1860 "MMP" 1861 "Vector Cantech" 1862 "Yamaha Marine" 1863 "Faria Instruments" ;
VAL_ 2650735360 Industry_Code 0 "Global" 1 "Highway" 2 "Agriculture" 3 "Construction" 4 "Marine Industry" 5 "Industrial" ;
VAL_ 2650735360 Manufacturer_Code 69 "ARKS Enterprises" 78 "FW Murphy/Enovation Controls" 80 "Twin Disc" 85 "Kohler Power Systems" 88 "Hemisphere GPS" 135 "Airmar" 137 "Maretron" 140 "Lowrance" 144 "Mercury Marine" 147 "Nautibus Electronic" 148 "Blue Water Data" 154 "Westerbeke" 157 "ISSPRO" 161 "Offshore Systems (UK)" 163 "Evinrude/BRP" 165 "CPAC Systems" 168 "Xantrex Technology" 169 "Marlin Technologies" 172 "Yanmar Marine" 174 "Volvo Penta" 176 "Carling Technologies Inc. (Moritz Aerospace)" 185 "Beede Instruments" 192 "Floscan Instrument" 193 "Nobeltec" 198 "Mystic Valley Communications" 199 "Actia" 201 "Disenos Y Technologia" 211 "Digital Switching Systems" 215 "Xintex/Atena" 224 "EMMI NETWORK" 228 "ZF" 229 "Garmin" 233 "Yacht Monitoring Solutions" 235 "Sailormade Marine Telemetry/Tetra Technology" 243 "Eride" 257 "Honda Motor" 272 "Groco" 273 "Actisense" 274 "Amphenol LTW Technology" 275 "Navico" 283 "Hamilton Jet" 285 "Sea Recovery" 286 "Coelmo SRL Italy" 295 "BEP Marine" 304 "Empir Bus" 305 "NovAtel" 306 "Sleipner Motor" 307 "MBW Technologies" 315 "ICOM" 328 "Qwerty" 329 "Dief" 341 "Boening Automationstechnologie" 345 "Korean Maritime University" 351 "Thrane and Thrane" 355 "Mastervolt" 356 "Fischer Panda Generators" 358 "Victron Energy" 370 "Rolls Royce Marine" 373 "Electronic Design" 374 "Northern Lights" 378 "Glendinning" 381 "B & G" 384 "Rose Point Navigation Systems" 385 "Johnson Outdoors Marine Electronics Inc Geonav" 394 "Capi 2" 396 "Beyond Measure" 400 "Livorsi Marine" 404 "ComNav" 409 "Chetco" 419 "Fusion Electronics" 421 "Standard Horizon" 422 "True Heading" 426 "Egersund Marine Electronics" 427 "em-trak Marine Electronics" 431 "Tohatsu Co, JP" 437 "Digital Yacht" 438 "Comar Systems Limited" 440 "Cummins" 443 "VDO (aka Continental-Corporation)" 451 "Parker Hannifin aka Village Marine Tech" 459 "Alltek Marine Electronics" 460 "SAN GIORGIO S.E.I.N" 466 "Veethree Electronics & Marine" 470 "SI-TEX Marine Electronics" 471 "Sea Cross Marine" 475 "GME aka Standard Communications" 476 "Humminbird Marine Electronics" 478 "Ocean Sat" 481 "Chetco Digital Instruments" 493 "Watcheye" 499 "Lcj Capteurs" 502 "Attwood Marine" 503 "Naviop S.R.L." 504 "Vesper Marine" 510 "Marinesoft" 513 "Simarine" 517 "NoLand Engineering" 518 "Transas USA" 529 "National Instruments Korea" 530 "National Marine Electronics Association" 532 "Onwa Marine" 540 "Webasto" 571 "Marinecraft (South Korea)" 573 "McMurdo Group aka Orolia" 578 "Advansea" 579 "KVH" 580 "San Jose Technology" 583 "Yacht Control" 586 "Suzuki Motor" 591 "US Coast Guard" 595 "Ship Module aka Customware" 600 "Aquatic AV" 605 "Aventics" 606 "Intellian" 612 "SamwonIT" 614 "Arlt Tecnologies" 637 "Bavaria Yachts" 641 "Diverse Yacht Services" 644 "Wema U.S.A dba KUS" 658 "Shenzhen Jiuzhou Himunication" 688 "Rockford" 699 "Harman International" 704 "JL Audio" 708 "Lars Thrane" 715 "Autonnic" 717 "Yacht Devices" 734 "REAP Systems" 735 "AEM Performance Electronics" 739 "LxNav" 741 "Littelfuse, Inc (formerly Carling Technologies)" 743 "DaeMyung" 744 "Woosung" 748 "ISOTTA IFRA srl" 773 "Clarion US" 776 "HMI Systems" 777 "Ocean Signal" 778 "Seakeeper" 781 "Poly Planar" 785 "Fischer Panda DE" 795 "Broyda Industries" 796 "Canadian Automotive" 797 "Tides Marine" 798 "Lumishore" 799 "Still Water Designs and Audio" 802 "BJ Technologies (Beneteau)" 803 "Gill Sensors" 811 "Blue Water Desalination" 815 "FLIR" 824 "Undheim Systems" 826 "Lewmar" 838 "TeamSurv" 844 "Fell Marine" 847 "Oceanvolt" 862 "Prospec" 868 "Data Panel" 890 "L3 Technologies" 894 "Rhodan Marine Systems" 896 "Nexfour Solutions" 905 "ASA Electronics" 909 "Marines Co (South Korea)" 911 "Nautic-on" 917 "Sentinel" 929 "JL Marine Systems" 930 "Ecotronix" 944 "Zontisa Marine" 951 "EXOR International" 962 "Timbolier Industries" 963 "TJC Micro" 968 "Cox Powertrain" 969 "Blue Seas" 981 "Kobelt Manufacturing" 992 "Blue Ocean IOT" 997 "Xenta Systems" 999 "Signal K" 1004 "Ultraflex" 1008 "Lintest SmartBoat" 1011 "Soundmax" 1020 "Team Italia Marine (Onyx Marine Automation s.r.l)" 1021 "Entratech" 1022 "ITC" 1029 "The Marine Guardian" 1047 "Sonic" 1051 "ProNav" 1053 "Vetus Maxwell INC." 1056 "Lithium Pros" 1059 "Boatrax" 1062 "Marol Co ltd" 1065 "CALYPSO Instruments" 1066 "Spot Zero Water" 1069 "Lithionics Battery" 1070 "Quick-teck Electronics" 1075 "Uniden America" 1083 "Nauticoncept" 1084 "Shadow-Caster LED lighting" 1085 "Wet Sounds" 1088 "E-T-A Circuit Breakers" 1092 "Scheiber" 1100 "Smart Yachts International Limited" 1109 "Dockmate" 1114 "Bobs Machine" 1118 "L3Harris ASV" 1119 "Balmar" 1120 "Elettromedia" 1127 "Electromaax" 1140 "Across Oceans Systems" 1145 "Kiwi Yachting" 1150 "BSB Artificial Intelligence" 1151 "Orca Technologies" 1154 "TBS Electronics" 1158 "Technoton Electroics" 1160 "MG Energy Systems" 1169 "Sea Machine Robotics" 1171 "Vista Manufacturing" 1183 "Zipwake" 1186 "Sailmon" 1192 "Airmoniq Pro Kft" 1194 "Sierra Marine" 1200 "Xinuo Information Technology (Xiamen)" 1218 "Septentrio" 1233 "NKE Marine Electronics" 1238 "SuperTrack Aps" 1239 "Honda Electronics" 1245 "Raritan Engineering" 1249 "Integrated Power Solutions AG" 1260 "Interactive Technologies" 1283 "LTG-Tech" 1299 "Energy Solutions (UK)" 1300 "WATT Fuel Cell" 1302 "Pro Mainer" 1305 "Dragonfly Energy" 1306 "Koden Electronics" 1311 "Humphree" 1316 "Hinkley Yachts" 1317 "Global Marine Management GmbH (GMM)" 1320 "Triskel Marine" 1330 "Warwick Control Technologies" 1331 "Dolphin Charger" 1337 "Barnacle Systems" 1348 "Radian IoT" 1353 "Ocean LED Marine" 1359 "BluNav" 1361 "OVA (Nantong Saiyang Electronics Co., Ltd)" 1368 "RAD Propulsion" 1369 "Electric Yacht" 1372 "Elco Motor Yachts" 1384 "Tecnoseal Foundry S.r.l" 1385 "Pro Charging Systems" 1389 "EVEX" 1398 "Gobius Sensor Technology" 1403 "Arco Marine" 1408 "Lenco Marine" 1413 "Naocontrol" 1417 "Revatek" 1438 "Aeolionics" 1439 "PredictWind" 1440 "Egis Mobile Electric" 1445 "Starboard Yacht Group" 1446 "Roswell Marine" 1451 "ePropulsion (Guangdong ePropulsion Technology Ltd.)" 1452 "Micro-Air" 1453 "Vital Battery" 1458 "Ride Controller" 1460 "Tocaro Blue" 1461 "Vanquish Yachts" 1471 "FT Technologies" 1478 "Alps Alpine" 1481 "E-Force Marine" 1482 "CMC Marine" 1483 "Nanjing Sandemarine Information Technology" 1850 "Teleflex Marine (SeaStar Solutions)" 1851 "Raymarine" 1852 "Navionics" 1853 "Japan Radio" 1854 "Northstar Technologies" 1855 "Furuno" 1856 "Trimble" 1857 "Simrad" 1858 "Litton" 1859 "Kvasar" 1860 "MMP" 1861 "Vector Cantech" 1862 "Yamaha Marine" 1863 "Faria Instruments" ;
VAL_ 2650735360 Industry_Code 0 "Global" 1 "Highway" 2 "Agriculture" 3 "Construction" 4 "Marine Industry" 5 "Industrial" ;
VAL_ 2650735360 Alert_Type 1 "Emergency Alarm" 2 "Alarm" 5 "Warning" 8 "Caution" ;
VAL_ 2650735360 Alert_Category 0 "Navigational" 1 "Technical" ;
VAL_ 2650735360 Manufacturer_Code 69 "ARKS Enterprises" 78 "FW Murphy/Enovation Controls" 80 "Twin Disc" 85 "Kohler Power Systems" 88 "Hemisphere GPS" 135 "Airmar" 137 "Maretron" 140 "Lowrance" 144 "Mercury Marine" 147 "Nautibus Electronic" 148 "Blue Water Data" 154 "Westerbeke" 157 "ISSPRO" 161 "Offshore Systems (UK)" 163 "Evinrude/BRP" 165 "CPAC Systems" 168 "Xantrex Technology" 169 "Marlin Technologies" 172 "Yanmar Marine" 174 "Volvo Penta" 176 "Carling Technologies Inc. (Moritz Aerospace)" 185 "Beede Instruments" 192 "Floscan Instrument" 193 "Nobeltec" 198 "Mystic Valley Communications" 199 "Actia" 201 "Disenos Y Technologia" 211 "Digital Switching Systems" 215 "Xintex/Atena" 224 "EMMI NETWORK" 228 "ZF" 229 "Garmin" 233 "Yacht Monitoring Solutions" 235 "Sailormade Marine Telemetry/Tetra Technology" 243 "Eride" 257 "Honda Motor" 272 "Groco" 273 "Actisense" 274 "Amphenol LTW Technology" 275 "Navico" 283 "Hamilton Jet" 285 "Sea Recovery" 286 "Coelmo SRL Italy" 295 "BEP Marine" 304 "Empir Bus" 305 "NovAtel" 306 "Sleipner Motor" 307 "MBW Technologies" 315 "ICOM" 328 "Qwerty" 329 "Dief" 341 "Boening Automationstechnologie" 345 "Korean Maritime University" 351 "Thrane and Thrane" 355 "Mastervolt" 356 "Fischer Panda Generators" 358 "Victron Energy" 370 "Rolls Royce Marine" 373 "Electronic Design" 374 "Northern Lights" 378 "Glendinning" 381 "B & G" 384 "Rose Point Navigation Systems" 385 "Johnson Outdoors Marine Electronics Inc Geonav" 394 "Capi 2" 396 "Beyond Measure" 400 "Livorsi Marine" 404 "ComNav" 409 "Chetco" 419 "Fusion Electronics" 421 "Standard Horizon" 422 "True Heading" 426 "Egersund Marine Electronics" 427 "em-trak Marine Electronics" 431 "Tohatsu Co, JP" 437 "Digital Yacht" 438 "Comar Systems Limited" 440 "Cummins" 443 "VDO (aka Continental-Corporation)" 451 "Parker Hannifin aka Village Marine Tech" 459 "Alltek Marine Electronics" 460 "SAN GIORGIO S.E.I.N" 466 "Veethree Electronics & Marine" 470 "SI-TEX Marine Electronics" 471 "Sea Cross Marine" 475 "GME aka Standard Communications" 476 "Humminbird Marine Electronics" 478 "Ocean Sat" 481 "Chetco Digital Instruments" 493 "Watcheye" 499 "Lcj Capteurs" 502 "Attwood Marine" 503 "Naviop S.R.L." 504 "Vesper Marine" 510 "Marinesoft" 513 "Simarine" 517 "NoLand Engineering" 518 "Transas USA" 529 "National Instruments Korea" 530 "National Marine Electronics Association" 532 "Onwa Marine" 540 "Webasto" 571 "Marinecraft (South Korea)" 573 "McMurdo Group aka Orolia" 578 "Advansea" 579 "KVH" 580 "San Jose Technology" 583 "Yacht Control" 586 "Suzuki Motor" 591 "US Coast Guard" 595 "Ship Module aka Customware" 600 "Aquatic AV" 605 "Aventics" 606 "Intellian" 612 "SamwonIT" 614 "Arlt Tecnologies" 637 "Bavaria Yachts" 641 "Diverse Yacht Services" 644 "Wema U.S.A dba KUS" 658 "Shenzhen Jiuzhou Himunication" 688 "Rockford" 699 "Harman International" 704 "JL Audio" 708 "Lars Thrane" 715 "Autonnic" 717 "Yacht Devices" 734 "REAP Systems" 735 "AEM Performance Electronics" 739 "LxNav" 741 "Littelfuse, Inc (formerly Carling Technologies)" 743 "DaeMyung" 744 "Woosung" 748 "ISOTTA IFRA srl" 773 "Clarion US" 776 "HMI Systems" 777 "Ocean Signal" 778 "Seakeeper" 781 "Poly Planar" 785 "Fischer Panda DE" 795 "Broyda Industries" 796 "Canadian Automotive" 797 "Tides Marine" 798 "Lumishore" 799 "Still Water Designs and Audio" 802 "BJ Technologies (Beneteau)" 803 "Gill Sensors" 811 "Blue Water Desalination" 815 "FLIR" 824 "Undheim Systems" 826 "Lewmar" 838 "TeamSurv" 844 "Fell Marine" 847 "Oceanvolt" 862 "Prospec" 868 "Data Panel" 890 "L3 Technologies" 894 "Rhodan Marine Systems" 896 "Nexfour Solutions" 905 "ASA Electronics" 909 "Marines Co (South Korea)" 911 "Nautic-on" 917 "Sentinel" 929 "JL Marine Systems" 930 "Ecotronix" 944 "Zontisa Marine" 951 "EXOR International" 962 "Timbolier Industries" 963 "TJC Micro" 968 "Cox Powertrain" 969 "Blue Seas" 981 "Kobelt Manufacturing" 992 "Blue Ocean IOT" 997 "Xenta Systems" 999 "Signal K" 1004 "Ultraflex" 1008 "Lintest SmartBoat" 1011 "Soundmax" 1020 "Team Italia Marine (Onyx Marine Automation s.r.l)" 1021 "Entratech" 1022 "ITC" 1029 "The Marine Guardian" 1047 "Sonic" 1051 "ProNav" 1053 "Vetus Maxwell INC." 1056 "Lithium Pros" 1059 "Boatrax" 1062 "Marol Co ltd" 1065 "CALYPSO Instruments" 1066 "Spot Zero Water" 1069 "Lithionics Battery" 1070 "Quick-teck Electronics" 1075 "Uniden America" 1083 "Nauticoncept" 1084 "Shadow-Caster LED lighting" 1085 "Wet Sounds" 1088 "E-T-A Circuit Breakers" 1092 "Scheiber" 1100 "Smart Yachts International Limited" 1109 "Dockmate" 1114 "Bobs Machine" 1118 "L3Harris ASV" 1119 "Balmar" 1120 "Elettromedia" 1127 "Electromaax" 1140 "Across Oceans Systems" 1145 "Kiwi Yachting" 1150 "BSB Artificial Intelligence" 1151 "Orca Technologies" 1154 "TBS Electronics" 1158 "Technoton Electroics" 1160 "MG Energy Systems" 1169 "Sea Machine Robotics" 1171 "Vista Manufacturing" 1183 "Zipwake" 1186 "Sailmon" 1192 "Airmoniq Pro Kft" 1194 "Sierra Marine" 1200 "Xinuo Information Technology (Xiamen)" 1218 "Septentrio" 1233 "NKE Marine Electronics" 1238 "SuperTrack Aps" 1239 "Honda Electronics" 1245 "Raritan Engineering" 1249 "Integrated Power Solutions AG" 1260 "Interactive Technologies" 1283 "LTG-Tech" 1299 "Energy Solutions (UK)" 1300 "WATT Fuel Cell" 1302 "Pro Mainer" 1305 "Dragonfly Energy" 1306 "Koden Electronics" 1311 "Humphree" 1316 "Hinkley Yachts" 1317 "Global Marine Management GmbH (GMM)" 1320 "Triskel Marine" 1330 "Warwick Control Technologies" 1331 "Dolphin Charger" 1337 "Barnacle Systems" 1348 "Radian IoT" 1353 "Ocean LED Marine" 1359 "BluNav" 1361 "OVA (Nantong Saiyang Electronics Co., Ltd)" 1368 "RAD Propulsion" 1369 "Electric Yacht" 1372 "Elco Motor Yachts" 1384 "Tecnoseal Foundry S.r.l" 1385 "Pro Charging Systems" 1389 "EVEX" 1398 "Gobius Sensor Technology" 1403 "Arco Marine" 1408 "Lenco Marine" 1413 "Naocontrol" 1417 "Revatek" 1438 "Aeolionics" 1439 "PredictWind" 1440 "Egis Mobile Electric" 1445 "Starboard Yacht Group" 1446 "Roswell Marine" 1451 "ePropulsion (Guangdong ePropulsion Technology Ltd.)" 1452 "Micro-Air" 1453 "Vital Battery" 1458 "Ride Controller" 1460 "Tocaro Blue" 1461 "Vanquish Yachts" 1471 "FT Technologies" 1478 "Alps Alpine" 1481 "E-Force Marine" 1482 "CMC Marine" 1483 "Nanjing Sandemarine Information Technology" 1850 "Teleflex Marine (SeaStar Solutions)" 1851 "Raymarine" 1852 "Navionics" 1853 "Japan Radio" 1854 "Northstar Technologies" 1855 "Furuno" 1856 "Trimble" 1857 "Simrad" 1858 "Litton" 1859 "Kvasar" 1860 "MMP" 1861 "Vector Cantech" 1862 "Yamaha Marine" 1863 "Faria Instruments" ;
VAL_ 2650735360 Industry_Code 0 "Global" 1 "Highway" 2 "Agriculture" 3 "Construction" 4 "Marine Industry" 5 "Industrial" ;
VAL_ 2382299904 Manufacturer_Code 69 "ARKS Enterprises" 78 "FW Murphy/Enovation Controls" 80 "Twin Disc" 85 "Kohler Power Systems" 88 "Hemisphere GPS" 135 "Airmar" 137 "Maretron" 140 "Lowrance" 144 "Mercury Marine" 147 "Nautibus Electronic" 148 "Blue Water Data" 154 "Westerbeke" 157 "ISSPRO" 161 "Offshore Systems (UK)" 163 "Evinrude/BRP" 165 "CPAC Systems" 168 "Xantrex Technology" 169 "Marlin Technologies" 172 "Yanmar Marine" 174 "Volvo Penta" 176 "Carling Technologies Inc. (Moritz Aerospace)" 185 "Beede Instruments" 192 "Floscan Instrument" 193 "Nobeltec" 198 "Mystic Valley Communications" 199 "Actia" 201 "Disenos Y Technologia" 211 "Digital Switching Systems" 215 "Xintex/Atena" 224 "EMMI NETWORK" 228 "ZF" 229 "Garmin" 233 "Yacht Monitoring Solutions" 235 "Sailormade Marine Telemetry/Tetra Technology" 243 "Eride" 257 "Honda Motor" 272 "Groco" 273 "Actisense" 274 "Amphenol LTW Technology" 275 "Navico" 283 "Hamilton Jet" 285 "Sea Recovery" 286 "Coelmo SRL Italy" 295 "BEP Marine" 304 "Empir Bus" 305 "NovAtel" 306 "Sleipner Motor" 307 "MBW Technologies" 315 "ICOM" 328 "Qwerty" 329 "Dief" 341 "Boening Automationstechnologie" 345 "Korean Maritime University" 351 "Thrane and Thrane" 355 "Mastervolt" 356 "Fischer Panda Generators" 358 "Victron Energy" 370 "Rolls Royce Marine" 373 "Electronic Design" 374 "Northern Lights" 378 "Glendinning" 381 "B & G" 384 "Rose Point Navigation Systems" 385 "Johnson Outdoors Marine Electronics Inc Geonav" 394 "Capi 2" 396 "Beyond Measure" 400 "Livorsi Marine" 404 "ComNav" 409 "Chetco" 419 "Fusion Electronics" 421 "Standard Horizon" 422 "True Heading" 426 "Egersund Marine Electronics" 427 "em-trak Marine Electronics" 431 "Tohatsu Co, JP" 437 "Digital Yacht" 438 "Comar Systems Limited" 440 "Cummins" 443 "VDO (aka Continental-Corporation)" 451 "Parker Hannifin aka Village Marine Tech" 459 "Alltek Marine Electronics" 460 "SAN GIORGIO S.E.I.N" 466 "Veethree Electronics & Marine" 470 "SI-TEX Marine Electronics" 471 "Sea Cross Marine" 475 "GME aka Standard Communications" 476 "Humminbird Marine Electronics" 478 "Ocean Sat" 481 "Chetco Digital Instruments" 493 "Watcheye" 499 "Lcj Capteurs" 502 "Attwood Marine" 503 "Naviop S.R.L." 504 "Vesper Marine" 510 "Marinesoft" 513 "Simarine" 517 "NoLand Engineering" 518 "Transas USA" 529 "National Instruments Korea" 530 "National Marine Electronics Association" 532 "Onwa Marine" 540 "Webasto" 571 "Marinecraft (South Korea)" 573 "McMurdo Group aka Orolia" 578 "Advansea" 579 "KVH" 580 "San Jose Technology" 583 "Yacht Control" 586 "Suzuki Motor" 591 "US Coast Guard" 595 "Ship Module aka Customware" 600 "Aquatic AV" 605 "Aventics" 606 "Intellian" 612 "SamwonIT" 614 "Arlt Tecnologies" 637 "Bavaria Yachts" 641 "Diverse Yacht Services" 644 "Wema U.S.A dba KUS" 658 "Shenzhen Jiuzhou Himunication" 688 "Rockford" 699 "Harman International" 704 "JL Audio" 708 "Lars Thrane" 715 "Autonnic" 717 "Yacht Devices" 734 "REAP Systems" 735 "AEM Performance Electronics" 739 "LxNav" 741 "Littelfuse, Inc (formerly Carling Technologies)" 743 "DaeMyung" 744 "Woosung" 748 "ISOTTA IFRA srl" 773 "Clarion US" 776 "HMI Systems" 777 "Ocean Signal" 778 "Seakeeper" 781 "Poly Planar" 785 "Fischer Panda DE" 795 "Broyda Industries" 796 "Canadian Automotive" 797 "Tides Marine" 798 "Lumishore" 799 "Still Water Designs and Audio" 802 "BJ Technologies (Beneteau)" 803 "Gill Sensors" 811 "Blue Water Desalination" 815 "FLIR" 824 "Undheim Systems" 826 "Lewmar" 838 "TeamSurv" 844 "Fell Marine" 847 "Oceanvolt" 862 "Prospec" 868 "Data Panel" 890 "L3 Technologies" 894 "Rhodan Marine Systems" 896 "Nexfour Solutions" 905 "ASA Electronics" 909 "Marines Co (South Korea)" 911 "Nautic-on" 917 "Sentinel" 929 "JL Marine Systems" 930 "Ecotronix" 944 "Zontisa Marine" 951 "EXOR International" 962 "Timbolier Industries" 963 "TJC Micro" 968 "Cox Powertrain" 969 "Blue Seas" 981 "Kobelt Manufacturing" 992 "Blue Ocean IOT" 997 "Xenta Systems" 999 "Signal K" 1004 "Ultraflex" 1008 "Lintest SmartBoat" 1011 "Soundmax" 1020 "Team Italia Marine (Onyx Marine Automation s.r.l)" 1021 "Entratech" 1022 "ITC" 1029 "The Marine Guardian" 1047 "Sonic" 1051 "ProNav" 1053 "Vetus Maxwell INC." 1056 "Lithium Pros" 1059 "Boatrax" 1062 "Marol Co ltd" 1065 "CALYPSO Instruments" 1066 "Spot Zero Water" 1069 "Lithionics Battery" 1070 "Quick-teck Electronics" 1075 "Uniden America" 1083 "Nauticoncept" 1084 "Shadow-Caster LED lighting" 1085 "Wet Sounds" 1088 "E-T-A Circuit Breakers" 1092 "Scheiber" 1100 "Smart Yachts International Limited" 1109 "Dockmate" 1114 "Bobs Machine" 1118 "L3Harris ASV" 1119 "Balmar" 1120 "Elettromedia" 1127 "Electromaax" 1140 "Across Oceans Systems" 1145 "Kiwi Yachting" 1150 "BSB Artificial Intelligence" 1151 "Orca Technologies" 1154 "TBS Electronics" 1158 "Technoton Electroics" 1160 "MG Energy Systems" 1169 "Sea Machine Robotics" 1171 "Vista Manufacturing" 1183 "Zipwake" 1186 "Sailmon" 1192 "Airmoniq Pro Kft" 1194 "Sierra Marine" 1200 "Xinuo Information Technology (Xiamen)" 1218 "Septentrio" 1233 "NKE Marine Electronics" 1238 "SuperTrack Aps" 1239 "Honda Electronics" 1245 "Raritan Engineering" 1249 "Integrated Power Solutions AG" 1260 "Interactive Technologies" 1283 "LTG-Tech" 1299 "Energy Solutions (UK)" 1300 "WATT Fuel Cell" 1302 "Pro Mainer" 1305 "Dragonfly Energy" 1306 "Koden Electronics" 1311 "Humphree" 1316 "Hinkley Yachts" 1317 "Global Marine Management GmbH (GMM)" 1320 "Triskel Marine" 1330 "Warwick Control Technologies" 1331 "Dolphin Charger" 1337 "Barnacle Systems" 1348 "Radian IoT" 1353 "Ocean LED Marine" 1359 "BluNav" 1361 "OVA (Nantong Saiyang Electronics Co., Ltd)" 1368 "RAD Propulsion" 1369 "Electric Yacht" 1372 "Elco Motor Yachts" 1384 "Tecnoseal Foundry S.r.l" 1385 "Pro Charging Systems" 1389 "EVEX" 1398 "Gobius Sensor Technology" 1403 "Arco Marine" 1408 "Lenco Marine" 1413 "Naocontrol" 1417 "Revatek" 1438 "Aeolionics" 1439 "PredictWind" 1440 "Egis Mobile Electric" 1445 "Starboard Yacht Group" 1446 "Roswell Marine" 1451 "ePropulsion (Guangdong ePropulsion Technology Ltd.)" 1452 "Micro-Air" 1453 "Vital Battery" 1458 "Ride Controller" 1460 "Tocaro Blue" 1461 "Vanquish Yachts" 1471 "FT Technologies" 1478 "Alps Alpine" 1481 "E-Force Marine" 1482 "CMC Marine" 1483 "Nanjing Sandemarine Information Technology" 1850 "Teleflex Marine (SeaStar Solutions)" 1851 "Raymarine" 1852 "Navionics" 1853 "Japan Radio" 1854 "Northstar Technologies" 1855 "Furuno" 1856 "Trimble" 1857 "Simrad" 1858 "Litton" 1859 "Kvasar" 1860 "MMP" 1861 "Vector Cantech" 1862 "Yamaha Marine" 1863 "Faria Instruments" ;
VAL_ 2382299904 Industry_Code 0 "Global" 1 "Highway" 2 "Agriculture" 3 "Construction" 4 "Marine Industry" 5 "Industrial" ;
VAL_ 2382299904 Unit_On_Off 0 "Off" 1 "On" ;
VAL_ 2583626752 Manufacturer_Code 69 "ARKS Enterprises" 78 "FW Murphy/Enovation Controls" 80 "Twin Disc" 85 "Kohler Power Systems" 88 "Hemisphere GPS" 135 "Airmar" 137 "Maretron" 140 "Lowrance" 144 "Mercury Marine" 147 "Nautibus Electronic" 148 "Blue Water Data" 154 "Westerbeke" 157 "ISSPRO" 161 "Offshore Systems (UK)" 163 "Evinrude/BRP" 165 "CPAC Systems" 168 "Xantrex Technology" 169 "Marlin Technologies" 172 "Yanmar Marine" 174 "Volvo Penta" 176 "Carling Technologies Inc. (Moritz Aerospace)" 185 "Beede Instruments" 192 "Floscan Instrument" 193 "Nobeltec" 198 "Mystic Valley Communications" 199 "Actia" 201 "Disenos Y Technologia" 211 "Digital Switching Systems" 215 "Xintex/Atena" 224 "EMMI NETWORK" 228 "ZF" 229 "Garmin" 233 "Yacht Monitoring Solutions" 235 "Sailormade Marine Telemetry/Tetra Technology" 243 "Eride" 257 "Honda Motor" 272 "Groco" 273 "Actisense" 274 "Amphenol LTW Technology" 275 "Navico" 283 "Hamilton Jet" 285 "Sea Recovery" 286 "Coelmo SRL Italy" 295 "BEP Marine" 304 "Empir Bus" 305 "NovAtel" 306 "Sleipner Motor" 307 "MBW Technologies" 315 "ICOM" 328 "Qwerty" 329 "Dief" 341 "Boening Automationstechnologie" 345 "Korean Maritime University" 351 "Thrane and Thrane" 355 "Mastervolt" 356 "Fischer Panda Generators" 358 "Victron Energy" 370 "Rolls Royce Marine" 373 "Electronic Design" 374 "Northern Lights" 378 "Glendinning" 381 "B & G" 384 "Rose Point Navigation Systems" 385 "Johnson Outdoors Marine Electronics Inc Geonav" 394 "Capi 2" 396 "Beyond Measure" 400 "Livorsi Marine" 404 "ComNav" 409 "Chetco" 419 "Fusion Electronics" 421 "Standard Horizon" 422 "True Heading" 426 "Egersund Marine Electronics" 427 "em-trak Marine Electronics" 431 "Tohatsu Co, JP" 437 "Digital Yacht" 438 "Comar Systems Limited" 440 "Cummins" 443 "VDO (aka Continental-Corporation)" 451 "Parker Hannifin aka Village Marine Tech" 459 "Alltek Marine Electronics" 460 "SAN GIORGIO S.E.I.N" 466 "Veethree Electronics & Marine" 470 "SI-TEX Marine Electronics" 471 "Sea Cross Marine" 475 "GME aka Standard Communications" 476 "Humminbird Marine Electronics" 478 "Ocean Sat" 481 "Chetco Digital Instruments" 493 "Watcheye" 499 "Lcj Capteurs" 502 "Attwood Marine" 503 "Naviop S.R.L." 504 "Vesper Marine" 510 "Marinesoft" 513 "Simarine" 517 "NoLand Engineering" 518 "Transas USA" 529 "National Instruments Korea" 530 "National Marine Electronics Association" 532 "Onwa Marine" 540 "Webasto" 571 "Marinecraft (South Korea)" 573 "McMurdo Group aka Orolia" 578 "Advansea" 579 "KVH" 580 "San Jose Technology" 583 "Yacht Control" 586 "Suzuki Motor" 591 "US Coast Guard" 595 "Ship Module aka Customware" 600 "Aquatic AV" 605 "Aventics" 606 "Intellian" 612 "SamwonIT" 614 "Arlt Tecnologies" 637 "Bavaria Yachts" 641 "Diverse Yacht Services" 644 "Wema U.S.A dba KUS" 658 "Shenzhen Jiuzhou Himunication" 688 "Rockford" 699 "Harman International" 704 "JL Audio" 708 "Lars Thrane" 715 "Autonnic" 717 "Yacht Devices" 734 "REAP Systems" 735 "AEM Performance Electronics" 739 "LxNav" 741 "Littelfuse, Inc (formerly Carling Technologies)" 743 "DaeMyung" 744 "Woosung" 748 "ISOTTA IFRA srl" 773 "Clarion US" 776 "HMI Systems" 777 "Ocean Signal" 778 "Seakeeper" 781 "Poly Planar" 785 "Fischer Panda DE" 795 "Broyda Industries" 796 "Canadian Automotive" 797 "Tides Marine" 798 "Lumishore" 799 "Still Water Designs and Audio" 802 "BJ Technologies (Beneteau)" 803 "Gill Sensors" 811 "Blue Water Desalination" 815 "FLIR" 824 "Undheim Systems" 826 "Lewmar" 838 "TeamSurv" 844 "Fell Marine" 847 "Oceanvolt" 862 "Prospec" 868 "Data Panel" 890 "L3 Technologies" 894 "Rhodan Marine Systems" 896 "Nexfour Solutions" 905 "ASA Electronics" 909 "Marines Co (South Korea)" 911 "Nautic-on" 917 "Sentinel" 929 "JL Marine Systems" 930 "Ecotronix" 944 "Zontisa Marine" 951 "EXOR International" 962 "Timbolier Industries" 963 "TJC Micro" 968 "Cox Powertrain" 969 "Blue Seas" 981 "Kobelt Manufacturing" 992 "Blue Ocean IOT" 997 "Xenta Systems" 999 "Signal K" 1004 "Ultraflex" 1008 "Lintest SmartBoat" 1011 "Soundmax" 1020 "Team Italia Marine (Onyx Marine Automation s.r.l)" 1021 "Entratech" 1022 "ITC" 1029 "The Marine Guardian" 1047 "Sonic" 1051 "ProNav" 1053 "Vetus Maxwell INC." 1056 "Lithium Pros" 1059 "Boatrax" 1062 "Marol Co ltd" 1065 "CALYPSO Instruments" 1066 "Spot Zero Water" 1069 "Lithionics Battery" 1070 "Quick-teck Electronics" 1075 "Uniden America" 1083 "Nauticoncept" 1084 "Shadow-Caster LED lighting" 1085 "Wet Sounds" 1088 "E-T-A Circuit Breakers" 1092 "Scheiber" 1100 "Smart Yachts International Limited" 1109 "Dockmate" 1114 "Bobs Machine" 1118 "L3Harris ASV" 1119 "Balmar" 1120 "Elettromedia" 1127 "Electromaax" 1140 "Across Oceans Systems" 1145 "Kiwi Yachting" 1150 "BSB Artificial Intelligence" 1151 "Orca Technologies" 1154 "TBS Electronics" 1158 "Technoton Electroics" 1160 "MG Energy Systems" 1169 "Sea Machine Robotics" 1171 "Vista Manufacturing" 1183 "Zipwake" 1186 "Sailmon" 1192 "Airmoniq Pro Kft" 1194 "Sierra Marine" 1200 "Xinuo Information Technology (Xiamen)" 1218 "Septentrio" 1233 "NKE Marine Electronics" 1238 "SuperTrack Aps" 1239 "Honda Electronics" 1245 "Raritan Engineering" 1249 "Integrated Power Solutions AG" 1260 "Interactive Technologies" 1283 "LTG-Tech" 1299 "Energy Solutions (UK)" 1300 "WATT Fuel Cell" 1302 "Pro Mainer" 1305 "Dragonfly Energy" 1306 "Koden Electronics" 1311 "Humphree" 1316 "Hinkley Yachts" 1317 "Global Marine Management GmbH (GMM)" 1320 "Triskel Marine" 1330 "Warwick Control Technologies" 1331 "Dolphin Charger" 1337 "Barnacle Systems" 1348 "Radian IoT" 1353 "Ocean LED Marine" 1359 "BluNav" 1361 "OVA (Nantong Saiyang Electronics Co., Ltd)" 1368 "RAD Propulsion" 1369 "Electric Yacht" 1372 "Elco Motor Yachts" 1384 "Tecnoseal Foundry S.r.l" 1385 "Pro Charging Systems" 1389 "EVEX" 1398 "Gobius Sensor Technology" 1403 "Arco Marine" 1408 "Lenco Marine" 1413 "Naocontrol" 1417 "Revatek" 1438 "Aeolionics" 1439 "PredictWind" 1440 "Egis Mobile Electric" 1445 "Starboard Yacht Group" 1446 "Roswell Marine" 1451 "ePropulsion (Guangdong ePropulsion Technology Ltd.)" 1452 "Micro-Air" 1453 "Vital Battery" 1458 "Ride Controller" 1460 "Tocaro Blue" 1461 "Vanquish Yachts" 1471 "FT Technologies" 1478 "Alps Alpine" 1481 "E-Force Marine" 1482 "CMC Marine" 1483 "Nanjing Sandemarine Information Technology" 1850 "Teleflex Marine (SeaStar Solutions)" 1851 "Raymarine" 1852 "Navionics" 1853 "Japan Radio" 1854 "Northstar Technologies" 1855 "Furuno" 1856 "Trimble" 1857 "Simrad" 1858 "Litton" 1859 "Kvasar" 1860 "MMP" 1861 "Vector Cantech" 1862 "Yamaha Marine" 1863 "Faria Instruments" ;
VAL_ 2583626752 Industry_Code 0 "Global" 1 "Highway" 2 "Agriculture" 3 "Construction" 4 "Marine Industry" 5 "Industrial" ;
CM_ SG_ 2650734848 Model "STRING field: decode bytes as ASCII (0x00/@/0xFF = terminator); canboat type: STRING_FIX";
CM_ SG_ 2650734848 Firmware_version "STRING field: decode bytes as ASCII (0x00/@/0xFF = terminator); canboat type: STRING_FIX";
CM_ SG_ 2650734848 Firmware_date "STRING field: decode bytes as ASCII (0x00/@/0xFF = terminator); canboat type: STRING_FIX";
CM_ SG_ 2650734848 Firmware_time "STRING field: decode bytes as ASCII (0x00/@/0xFF = terminator); canboat type: STRING_FIX";
CM_ SG_ 2650735104 Label "STRING field: decode bytes as ASCII (0x00/@/0xFF = terminator); canboat type: STRING_LAU";

BA_DEF_ BO_ "GenMsgCycleTime" INT 0 60000;
BA_DEF_ BO_ "ProtocolType" STRING;

BA_DEF_ BO_ "J1939PGN" INT 0 262143;
BA_ "J1939PGN" BO_ 2650734848 130817;
BA_ "J1939PGN" BO_ 2650734848 130817;
BA_ "J1939PGN" BO_ 2650734848 130817;
BA_ "J1939PGN" BO_ 2583626240 130818;
BA_ "J1939PGN" BO_ 2650735104 130818;
BA_ "J1939PGN" BO_ 2650735104 130818;
BA_ "J1939PGN" BO_ 2650735104 130818;
BA_ "J1939PGN" BO_ 2583626240 130818;
BA_ "J1939PGN" BO_ 2583626496 130819;
BA_ "J1939PGN" BO_ 2650735360 130819;
BA_ "J1939PGN" BO_ 2650735360 130819;
BA_ "J1939PGN" BO_ 2650735360 130819;
BA_ "J1939PGN" BO_ 2382299904 130819;
BA_ "J1939PGN" BO_ 2583626752 130820;
BA_ "J1939PGN" BO_ 2650735616 130820;
BA_ "J1939PGN" BO_ 2650735616 130820;
BA_ "J1939PGN" BO_ 2650735616 130820;
BA_ "J1939PGN" BO_ 2650735616 130820;
BA_ "J1939PGN" BO_ 2650735616 130820;
BA_ "J1939PGN" BO_ 2650735616 130820;
BA_ "J1939PGN" BO_ 2650735616 130820;
BA_ "J1939PGN" BO_ 2650735616 130820;
BA_ "J1939PGN" BO_ 2650735616 130820;
BA_ "J1939PGN" BO_ 2650735616 130820;
BA_ "J1939PGN" BO_ 2650735616 130820;
BA_ "J1939PGN" BO_ 2650735616 130820;
BA_ "J1939PGN" BO_ 2650735616 130820;
BA_ "J1939PGN" BO_ 2650735616 130820;
BA_ "J1939PGN" BO_ 2650735616 130820;
BA_ "J1939PGN" BO_ 2650735616 130820;
BA_ "J1939PGN" BO_ 2650735616 130820;
BA_ "J1939PGN" BO_ 2650735616 130820;
BA_ "J1939PGN" BO_ 2650735616 130820;
BA_ "J1939PGN" BO_ 2650735616 130820;
BA_ "J1939PGN" BO_ 2650735616 130820;
BA_ "J1939PGN" BO_ 2650735616 130820;
BA_ "J1939PGN" BO_ 2650735616 130820;
BA_ "J1939PGN" BO_ 2650735616 130820;
BA_ "J1939PGN" BO_ 2650735616 130820;
BA_ "J1939PGN" BO_ 2650735616 130820;
BA_ "J1939PGN" BO_ 2650735616 130820;
BA_ "J1939PGN" BO_ 2650735616 130820;
BA_ "J1939PGN" BO_ 2650735616 130820;
BA_ "J1939PGN" BO_ 2650735616 130820;
BA_ "J1939PGN" BO_ 2650735616 130820;
BA_ "J1939PGN" BO_ 2650735616 130820;
BA_ "J1939PGN" BO_ 2650735616 130820;
BA_ "J1939PGN" BO_ 2650735616 130820;
BA_ "J1939PGN" BO_ 2650735616 130820;
BA_ "J1939PGN" BO_ 2650735616 130820;
BA_ "J1939PGN" BO_ 2650735616 130820;
BA_ "J1939PGN" BO_ 2650735616 130820;
BA_ "J1939PGN" BO_ 2650735616 130820;
BA_ "J1939PGN" BO_ 2650735616 130820;
BA_ "J1939PGN" BO_ 2650735616 130820;
BA_ "J1939PGN" BO_ 2650735616 130820;
BA_ "J1939PGN" BO_ 2650735616 130820;
BA_ "J1939PGN" BO_ 2650735616 130820;
BA_ "J1939PGN" BO_ 2650735616 130820;
BA_ "J1939PGN" BO_ 2650735616 130820;
BA_ "J1939PGN" BO_ 2650735616 130820;
BA_ "J1939PGN" BO_ 2650735616 130820;
BA_ "J1939PGN" BO_ 2650735616 130820;
BA_ "J1939PGN" BO_ 2650735616 130820;
